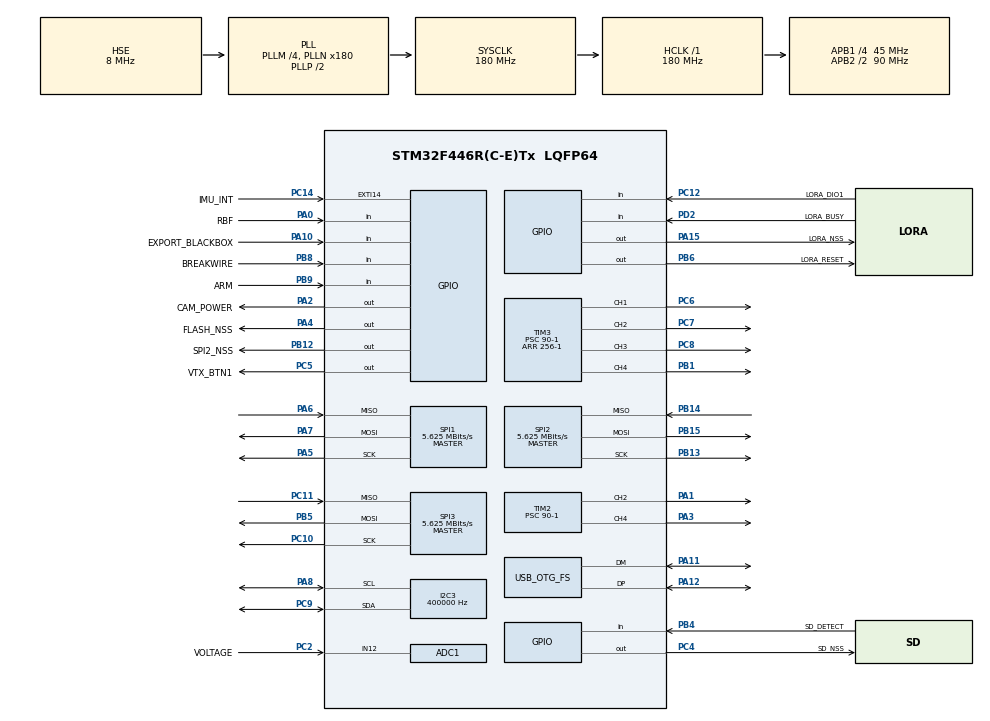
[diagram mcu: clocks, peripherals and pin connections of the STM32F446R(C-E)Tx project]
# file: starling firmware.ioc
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ADC1.Channel-3\#ChannelRegularConversion=ADC_CHANNEL_12
ADC1.NbrOfConversionFlag=1
ADC1.Rank-3\#ChannelRegularConversion=1
ADC1.SamplingTime-3\#ChannelRegularConversion=ADC_SAMPLETIME_3CYCLES
ADC1.master=1
Dma.Request0=SPI2_RX
Dma.Request1=SPI2_TX
Dma.Request2=SPI1_TX
Dma.SPI1_TX.2.Direction=DMA_MEMORY_TO_PERIPH
Dma.SPI1_TX.2.FIFOMode=DMA_FIFOMODE_DISABLE
Dma.SPI1_TX.2.Instance=DMA2_Stream3
Dma.SPI1_TX.2.MemDataAlignment=DMA_MDATAALIGN_BYTE
Dma.SPI1_TX.2.MemInc=DMA_MINC_ENABLE
Dma.SPI1_TX.2.Mode=DMA_NORMAL
Dma.SPI1_TX.2.PeriphDataAlignment=DMA_PDATAALIGN_BYTE
Dma.SPI1_TX.2.PeriphInc=DMA_PINC_DISABLE
Dma.SPI1_TX.2.Priority=DMA_PRIORITY_MEDIUM
Dma.SPI2_RX.0.Direction=DMA_PERIPH_TO_MEMORY
Dma.SPI2_RX.0.FIFOMode=DMA_FIFOMODE_DISABLE
Dma.SPI2_RX.0.Instance=DMA1_Stream3
Dma.SPI2_RX.0.MemDataAlignment=DMA_MDATAALIGN_BYTE
Dma.SPI2_RX.0.MemInc=DMA_MINC_ENABLE
Dma.SPI2_RX.0.Mode=DMA_NORMAL
Dma.SPI2_RX.0.PeriphDataAlignment=DMA_PDATAALIGN_BYTE
Dma.SPI2_RX.0.PeriphInc=DMA_PINC_DISABLE
Dma.SPI2_RX.0.Priority=DMA_PRIORITY_MEDIUM
Dma.SPI2_TX.1.Direction=DMA_MEMORY_TO_PERIPH
Dma.SPI2_TX.1.FIFOMode=DMA_FIFOMODE_DISABLE
Dma.SPI2_TX.1.Instance=DMA1_Stream4
Dma.SPI2_TX.1.MemDataAlignment=DMA_MDATAALIGN_BYTE
Dma.SPI2_TX.1.MemInc=DMA_MINC_ENABLE
Dma.SPI2_TX.1.Mode=DMA_NORMAL
Dma.SPI2_TX.1.PeriphDataAlignment=DMA_PDATAALIGN_BYTE
Dma.SPI2_TX.1.PeriphInc=DMA_PINC_DISABLE
Dma.SPI2_TX.1.Priority=DMA_PRIORITY_MEDIUM
FREERTOS.Queues01=BuzzerQueue,6,uint16_t,0,Dynamic,NULL,NULL
FREERTOS.Tasks01=ledTask,-1,128,StartLedTask,Default,NULL,Dynamic,NULL,NULL;musicTask,-3,128,StartMusicTask,Default,NULL,Dynamic,NULL,NULL;stateMachineTas,2,256,startStateMachine,Default,NULL,Dynamic,NULL,NULL;telemTask,0,256,StartTelemTask,Default,NULL,Dynamic,NULL,NULL;baroTask,0,128,StartBaroTask,Default,NULL,Dynamic,NULL,NULL;blackboxTask,-1,256,StartBlackboxTask,Default,NULL,Dynamic,NULL,NULL
FREERTOS.configENABLE_FPU=1
I2C3.ClockSpeed=400000
I2C3.I2C_Mode=I2C_Fast
Mcu.Family=STM32F4
Mcu.Name=STM32F446R(C-E)Tx
Mcu.Package=LQFP64
NVIC.DMA1_Stream3_IRQn=true\:5\:0\:false\:false\:true\:true\:false\:true
NVIC.DMA1_Stream4_IRQn=true\:5\:0\:false\:false\:true\:true\:false\:true
NVIC.DMA2_Stream3_IRQn=true\:5\:0\:false\:false\:true\:true\:false\:true
NVIC.EXTI15_10_IRQn=true\:5\:0\:false\:false\:true\:true\:true\:true
NVIC.OTG_FS_IRQn=true\:5\:0\:false\:false\:true\:true\:false\:true
NVIC.PriorityGroup=NVIC_PRIORITYGROUP_4
NVIC.TIM1_UP_TIM10_IRQn=true\:0\:0\:false\:false\:true\:false\:false\:true
NVIC.TimeBase=TIM1_UP_TIM10_IRQn
NVIC.TimeBaseIP=TIM1
PA0-WKUP.GPIO_Label=RBF
PA0-WKUP.GPIO_PuPd=GPIO_PULLUP
PA0-WKUP.Signal=GPIO_Input
PA1.Signal=S_TIM2_CH2
PA10.GPIO_Label=EXPORT_BLACKBOX
PA10.GPIO_PuPd=GPIO_PULLUP
PA10.Signal=GPIO_Input
PA11.Mode=Device_Only
PA11.Signal=USB_OTG_FS_DM
PA12.Mode=Device_Only
PA12.Signal=USB_OTG_FS_DP
PA13.Mode=Trace_Asynchronous_SW
PA13.Signal=SYS_JTMS-SWDIO
PA14.Mode=Trace_Asynchronous_SW
PA14.Signal=SYS_JTCK-SWCLK
PA15.GPIO_Label=LORA_NSS
PA15.Signal=GPIO_Output
PA2.GPIO_Label=CAM_POWER
PA2.Signal=GPIO_Output
PA3.Signal=S_TIM2_CH4
PA4.GPIO_Label=FLASH_NSS
PA4.Signal=GPIO_Output
PA5.Mode=Full_Duplex_Master
PA5.Signal=SPI1_SCK
PA6.Mode=Full_Duplex_Master
PA6.Signal=SPI1_MISO
PA7.Mode=Full_Duplex_Master
PA7.Signal=SPI1_MOSI
PA8.Mode=I2C
PA8.Signal=I2C3_SCL
PB1.Signal=S_TIM3_CH4
PB12.GPIO_Label=SPI2_NSS
PB12.Signal=GPIO_Output
PB13.Mode=Full_Duplex_Master
PB13.Signal=SPI2_SCK
PB14.Mode=Full_Duplex_Master
PB14.Signal=SPI2_MISO
PB15.Mode=Full_Duplex_Master
PB15.Signal=SPI2_MOSI
PB3.Mode=Trace_Asynchronous_SW
PB3.Signal=SYS_JTDO-SWO
PB4.GPIO_Label=SD_DETECT
PB4.Signal=GPIO_Input
PB5.Mode=Full_Duplex_Master
PB5.Signal=SPI3_MOSI
PB6.GPIO_Label=LORA_RESET
PB6.PinState=GPIO_PIN_SET
PB6.Signal=GPIO_Output
PB8.GPIO_Label=BREAKWIRE
PB8.GPIO_PuPd=GPIO_PULLUP
PB8.Signal=GPIO_Input
PB9.GPIO_Label=ARM
PB9.GPIO_PuPd=GPIO_PULLUP
PB9.Signal=GPIO_Input
PC10.Mode=Full_Duplex_Master
PC10.Signal=SPI3_SCK
PC11.Mode=Full_Duplex_Master
PC11.Signal=SPI3_MISO
PC12.GPIO_Label=LORA_DIO1
PC12.Signal=GPIO_Input
PC14-OSC32_IN.GPIO_Label=IMU_INT
PC14-OSC32_IN.Signal=GPXTI14
PC2.GPIO_Label=VOLTAGE
PC2.Signal=ADCx_IN12
PC4.GPIO_Label=SD_NSS
PC4.Signal=GPIO_Output
PC5.GPIO_Label=VTX_BTN1
PC5.GPIO_PuPd=GPIO_PULLDOWN
PC5.Signal=GPIO_Output
PC6.Signal=S_TIM3_CH1
PC7.Signal=S_TIM3_CH2
PC8.Signal=S_TIM3_CH3
PC9.Mode=I2C
PC9.Signal=I2C3_SDA
PD2.GPIO_Label=LORA_BUSY
PD2.Signal=GPIO_Input
PH0-OSC_IN.Mode=HSE-External-Oscillator
PH0-OSC_IN.Signal=RCC_OSC_IN
PH1-OSC_OUT.Mode=HSE-External-Oscillator
PH1-OSC_OUT.Signal=RCC_OSC_OUT
ProjectManager.HeapSize=0x200
ProjectManager.StackSize=0x400
ProjectManager.TargetToolchain=STM32CubeIDE
RCC.AHBFreq_Value=180000000
RCC.APB1CLKDivider=RCC_HCLK_DIV4
RCC.APB1Freq_Value=45000000
RCC.APB1TimFreq_Value=90000000
RCC.APB2CLKDivider=RCC_HCLK_DIV2
RCC.APB2Freq_Value=90000000
RCC.APB2TimFreq_Value=180000000
RCC.CortexFreq_Value=180000000
RCC.HCLKFreq_Value=180000000
RCC.HSE_VALUE=8000000
RCC.PLLM=4
RCC.PLLN=180
RCC.PLLQ=8
RCC.PLLSAIM=4
RCC.PLLSAIN=96
RCC.PLLSAIP=RCC_PLLSAIP_DIV4
RCC.PLLSourceVirtual=RCC_PLLSOURCE_HSE
RCC.SYSCLKFreq_VALUE=180000000
RCC.SYSCLKSource=RCC_SYSCLKSOURCE_PLLCLK
RCC.USBCLockSelection=RCC_CLK48CLKSOURCE_PLLSAIP
RCC.USBFreq_Value=48000000
RCC.VCOOutputFreq_Value=360000000
SH.ADCx_IN12.0=ADC1_IN12,IN12
SH.S_TIM2_CH2.0=TIM2_CH2,PWM Generation2 CH2
SH.S_TIM2_CH4.0=TIM2_CH4,PWM Generation4 CH4
SH.S_TIM3_CH1.0=TIM3_CH1,PWM Generation1 CH1
SH.S_TIM3_CH2.0=TIM3_CH2,PWM Generation2 CH2
SH.S_TIM3_CH3.0=TIM3_CH3,PWM Generation3 CH3
SH.S_TIM3_CH4.0=TIM3_CH4,PWM Generation4 CH4
SPI1.BaudRatePrescaler=SPI_BAUDRATEPRESCALER_16
SPI1.CalculateBaudRate=5.625 MBits/s
SPI1.Direction=SPI_DIRECTION_2LINES
SPI1.Mode=SPI_MODE_MASTER
SPI1.VirtualType=VM_MASTER
SPI2.BaudRatePrescaler=SPI_BAUDRATEPRESCALER_8
SPI2.CalculateBaudRate=5.625 MBits/s
SPI2.Direction=SPI_DIRECTION_2LINES
SPI2.Mode=SPI_MODE_MASTER
SPI2.VirtualType=VM_MASTER
SPI3.BaudRatePrescaler=SPI_BAUDRATEPRESCALER_8
SPI3.CalculateBaudRate=5.625 MBits/s
SPI3.Direction=SPI_DIRECTION_2LINES
SPI3.Mode=SPI_MODE_MASTER
SPI3.VirtualType=VM_MASTER
TIM2.Channel-PWM\ Generation2\ CH2=TIM_CHANNEL_2
TIM2.Channel-PWM\ Generation4\ CH4=TIM_CHANNEL_4
TIM2.Period=20000-1
TIM2.Prescaler=90-1
TIM2.Pulse-PWM\ Generation4\ CH4=0
TIM3.Channel-PWM\ Generation1\ CH1=TIM_CHANNEL_1
TIM3.Channel-PWM\ Generation2\ CH2=TIM_CHANNEL_2
TIM3.Channel-PWM\ Generation3\ CH3=TIM_CHANNEL_3
TIM3.Channel-PWM\ Generation4\ CH4=TIM_CHANNEL_4
TIM3.OCPolarity_1=TIM_OCPOLARITY_LOW
TIM3.OCPolarity_3=TIM_OCPOLARITY_LOW
TIM3.OCPolarity_4=TIM_OCPOLARITY_LOW
TIM3.Period=256-1
TIM3.Prescaler=90-1
TIM3.Pulse-PWM\ Generation4\ CH4=0
TIM6.Prescaler=90-1
USB_DEVICE.CLASS_NAME_FS=CDC
USB_DEVICE.VirtualMode-CDC_FS=Cdc
USB_DEVICE.VirtualModeFS=Cdc_FS
USB_OTG_FS.VirtualMode=Device_Only
USB_OTG_FS.low_power_enable=DISABLE
VP_FATFS_VS_Generic.Mode=User_defined
VP_FREERTOS_VS_CMSIS_V1.Mode=CMSIS_V1
VP_SYS_VS_tim1.Mode=TIM1
VP_TIM3_VS_ClockSourceINT.Mode=Internal
VP_TIM6_VS_ClockSourceINT.Mode=Enable_Timer
VP_USB_DEVICE_VS_USB_DEVICE_CDC_FS.Mode=CDC_FS
board=custom

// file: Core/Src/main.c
/* USER CODE BEGIN Header */
/**
 ******************************************************************************
 * @file           : main.c
 * @brief          : Main program body
 ******************************************************************************
 * @attention
 *
 * <h2><center>&copy; Copyright (c) 2021 STMicroelectronics.
 * All rights reserved.</center></h2>
 *
 * This software component is licensed by ST under BSD 3-Clause license,
 * the "License"; You may not use this file except in compliance with the
 * License. You may obtain a copy of the License at:
 *                        opensource.org/licenses/BSD-3-Clause
 *
 ******************************************************************************
 */
/* USER CODE END Header */
#include "main.h"
#include "cmsis_os.h"
#include "fatfs.h"
#include "usb_device.h"

/* USER CODE BEGIN Includes */

#include "usbd_cdc_if.h"
//#include "radio.h"
//#include "sx1280.h"
#include "sx1280_custom.h"
#include "SPL06.h"
#include "LSM6DSO32.h"
#include "servo.h"
#include "Quaternion.h"
#include "orientation.h"
#include "telemetry.h"
#include "w25qxx.h"

/* USER CODE END Includes */

/* USER CODE BEGIN PTD */
typedef enum {
    FLIGHT_ERROR = 0,
    SYSTEMS_CHECK = 1,
    IDLE = 2,
    PREPARATION = 3,
    ARMED = 4,
    LAUNCHED = 5,
    DEPLOYED = 6,
    LANDED = 7,
} state_type;

static state_type flight_state = SYSTEMS_CHECK;

static uint8_t servo_setting = 0;

typedef enum {
    REPEAT_BEEP = 0, KSP_MAIN = 1, RICK = 2, JINGLEBELL = 3,
} buzzer_sound;

static buzzer_sound buzzer_setting = KSP_MAIN;
static uint16_t buzzer_delay = 1000;

// extra (TODO):
uint32_t last_logged_deploy_time = 0;

uint8_t is_camera_recording = 0;
uint8_t is_camera_on = 0;

uint8_t is_data_logging = 0;

uint8_t ranging_enabled = 0;
uint8_t is_ranging_transponder = 0;

char blackbox_printBuffer[256];

flashblock chunk_of_flash;

uint8_t is_tx = 0;

// Music (Rick Astley)

#define  a3f    208     // 208 Hz
#define  b3f    233     // 233 Hz
#define  b3     247     // 247 Hz
#define  c4     261     // 261 Hz MIDDLE C
#define  c4s    277     // 277 Hz
#define  e4f    311     // 311 Hz
#define  f4     349     // 349 Hz
#define  a4f    415     // 415 Hz
#define  b4f    466     // 466 Hz
#define  b4     493     // 493 Hz
#define  c5     523     // 523 Hz
#define  c5s    554     // 554 Hz
#define  e5f    622     // 622 Hz
#define  f5     698     // 698 Hz
#define  f5s    740     // 740 Hz
#define  a5f    831     // 831 Hz

#define rest    -1
static uint16_t song1_intro_melody[] = { c5s, e5f, e5f, f5, a5f, f5s, f5, e5f,
        c5s, e5f, rest, a4f, a4f };

static uint16_t song1_intro_rhythmn[] = { 6, 10, 6, 6, 1, 1, 1, 1, 6, 10, 4, 2,
        10 };

static uint16_t song1_verse1_melody[] = { rest, c4s, c4s, c4s, c4s, e4f, rest,
        c4, b3f, a3f, rest, b3f, b3f, c4, c4s, a3f, a4f, a4f, e4f, rest, b3f,
        b3f, c4, c4s, b3f, c4s, e4f, rest, c4, b3f, b3f, a3f, rest, b3f, b3f,
        c4, c4s, a3f, a3f, e4f, e4f, e4f, f4, e4f, c4s, e4f, f4, c4s, e4f, e4f,
        e4f, f4, e4f, a3f, rest, b3f, c4, c4s, a3f, rest, e4f, f4, e4f };

static uint16_t song1_verse1_rhythmn[] = { 2, 1, 1, 1, 1, 2, 1, 1, 1, 5, 1, 1,
        1, 1, 3, 1, 2, 1, 5, 1, 1, 1, 1, 1, 1, 1, 2, 1, 1, 1, 1, 3, 1, 1, 1, 1,
        2, 1, 1, 1, 1, 1, 1, 4, 5, 1, 1, 1, 1, 1, 1, 1, 2, 2, 2, 1, 1, 1, 3, 1,
        1, 1, 3 };

static uint16_t song1_chorus_melody[] = { b4f, b4f, a4f, a4f, f5, f5, e5f, b4f,
        b4f, a4f, a4f, e5f, e5f, c5s, c5, b4f, c5s, c5s, c5s, c5s, c5s, e5f, c5,
        b4f, a4f, a4f, a4f, e5f, c5s, b4f, b4f, a4f, a4f, f5, f5, e5f, b4f, b4f,
        a4f, a4f, a5f, c5, c5s, c5, b4f, c5s, c5s, c5s, c5s, c5s, e5f, c5, b4f,
        a4f, rest, a4f, e5f, c5s, rest };

static uint16_t song1_chorus_rhythmn[] = { 1, 1, 1, 1, 3, 3, 6, 1, 1, 1, 1, 3,
        3, 3, 1, 2, 1, 1, 1, 1, 3, 3, 3, 1, 2, 2, 2, 4, 8, 1, 1, 1, 1, 3, 3, 6,
        1, 1, 1, 1, 3, 3, 3, 1, 2, 1, 1, 1, 1, 3, 3, 3, 1, 2, 2, 2, 4, 8, 4 };

// Music (KSP main theme)

static uint16_t ksp_tunes[] = {659, 523, 783, 523, 659, 784, 932, 880, 784, 523, 659, 784, 932, 880, 784, 523, 587, 698, 587, 523};
static uint16_t ksp_delays[] = {1000, 1000, 1000, 333, 333, 333, 1000, 1000, 1000, 333, 333, 333, 1000, 1000, 1000, 1000, 1000, 2000, 500, 500};

/* USER CODE END PTD */

/* USER CODE BEGIN PD */

// * 20 ms
#define BEEP_SHORT 12
#define BEEP_NORMAL 25
#define BEEP_LONG 50
#define BEEP_FOREVER 0xFF

#define VBAT_CALIBRATION 0.00456783157 // Based on schematic: 0.004592

// Flight settings:
#define MIN_DEPLOY_TIME 10000 // 10 seconds
#define MAX_DEPLOY_TIME 15000 // 15 seconds

#define BATTERY_EMPTY_LIMIT 7.2 //7.2 // volts
#define SERVO_CLOSED_POSITION 0 // degrees
#define SERVO_DEPLOY_POSITION 180 // degrees

#define OPTIMAL_BUZZER_FREQ 3000
#define OPTIMAL_BUZZER_DUTY 70

/* USER CODE END PD */

ADC_HandleTypeDef hadc1;

I2C_HandleTypeDef hi2c3;

SPI_HandleTypeDef hspi1;
SPI_HandleTypeDef hspi2;
SPI_HandleTypeDef hspi3;
DMA_HandleTypeDef hdma_spi1_tx;
DMA_HandleTypeDef hdma_spi2_rx;
DMA_HandleTypeDef hdma_spi2_tx;

TIM_HandleTypeDef htim2;
TIM_HandleTypeDef htim3;
TIM_HandleTypeDef htim6;

osThreadId ledTaskHandle;
osThreadId musicTaskHandle;
osThreadId stateMachineTasHandle;
osThreadId telemTaskHandle;
osThreadId baroTaskHandle;
osThreadId blackboxTaskHandle;
osMessageQId BuzzerQueueHandle;
/* USER CODE BEGIN PV */

lsm6dso imu;
uint8_t imu_ready = 0;

Orientation ori;
uint8_t apply_complementary = 1;

SPL06 baro;

/* USER CODE END PV */

void SystemClock_Config(void);
static void MX_GPIO_Init(void);
static void MX_DMA_Init(void);
static void MX_TIM3_Init(void);
static void MX_SPI2_Init(void);
static void MX_SPI3_Init(void);
static void MX_TIM2_Init(void);
static void MX_SPI1_Init(void);
static void MX_I2C3_Init(void);
static void MX_ADC1_Init(void);
static void MX_TIM6_Init(void);
void StartLedTask(void const * argument);
void StartMusicTask(void const * argument);
void startStateMachine(void const * argument);
void StartTelemTask(void const * argument);
void StartBaroTask(void const * argument);
void StartBlackboxTask(void const * argument);

/* USER CODE BEGIN PFP */

void playtone(uint16_t freq, uint16_t ms, uint8_t vol);
void changeLed(uint8_t ledR, uint8_t ledG, uint8_t ledB);
void jingleBell();
void rick();
void ksp();

float get_battery_voltage() {
    HAL_ADC_Start(&hadc1);
    HAL_ADC_PollForConversion(&hadc1, 100);
    float voltage = ((float) HAL_ADC_GetValue(&hadc1)) * VBAT_CALIBRATION;
    return voltage;
}

uint8_t is_armed() {
    return HAL_GPIO_ReadPin(RBF_GPIO_Port, RBF_Pin);// High corresponds to disconected = armed
}

uint8_t is_armed_debounce() {
    for (int i = 0; i < 20; i++) {
        if (!is_armed()) {
            return 0;
        }
        osDelay(1);
    }
    return 1;
}

uint8_t is_soft_enabled() {
    return HAL_GPIO_ReadPin(ARM_GPIO_Port, ARM_Pin);
}

uint8_t is_breakwire_connected() {
    return !HAL_GPIO_ReadPin(BREAKWIRE_GPIO_Port, BREAKWIRE_Pin);
}

uint8_t is_breakwire_broken_debounce() {
    for (int i = 0; i < 20; i++) {
        if (is_breakwire_connected()) {
            return 0;
        }
        osDelay(1);
    }
    return 1;
}

void buzzer_beep(uint8_t delayval) {
    buzzer_setting = REPEAT_BEEP;
    buzzer_delay = delayval * 20;

    if (osMessageAvailableSpace(BuzzerQueueHandle)) {
        osMessagePut(BuzzerQueueHandle, buzzer_delay, 100);
    }
}

void buzzer_clear_queue() {
    xQueueReset(BuzzerQueueHandle);
}

void pulse_recording_button() {
    HAL_GPIO_WritePin(VTX_BTN1_GPIO_Port, VTX_BTN1_Pin, GPIO_PIN_SET);
    osDelay(300);
    HAL_GPIO_WritePin(VTX_BTN1_GPIO_Port, VTX_BTN1_Pin, GPIO_PIN_RESET);
}

void double_pulse_recording() {
    HAL_GPIO_WritePin(VTX_BTN1_GPIO_Port, VTX_BTN1_Pin, GPIO_PIN_SET);
    osDelay(300);
    HAL_GPIO_WritePin(VTX_BTN1_GPIO_Port, VTX_BTN1_Pin, GPIO_PIN_RESET);
    osDelay(1000);
    HAL_GPIO_WritePin(VTX_BTN1_GPIO_Port, VTX_BTN1_Pin, GPIO_PIN_SET);
    osDelay(300);
    HAL_GPIO_WritePin(VTX_BTN1_GPIO_Port, VTX_BTN1_Pin, GPIO_PIN_RESET);

}

void enable_recording() {
    if (!is_camera_recording) {
        pulse_recording_button();
        is_camera_recording = 1;
    }
}

void disable_recording() {
    if (is_camera_recording) {
        pulse_recording_button();
        is_camera_recording = 0;
    }
}

void enable_camera() {
    HAL_GPIO_WritePin(CAM_POWER_GPIO_Port, CAM_POWER_Pin, GPIO_PIN_SET);
    is_camera_recording = 0;
    is_camera_on = 1;
}

void disable_camera() {
    if (is_camera_recording) {
        pulse_recording_button();
        osDelay(1000);
        is_camera_recording = 0;
    }
    is_camera_on = 0;
    HAL_GPIO_WritePin(CAM_POWER_GPIO_Port, CAM_POWER_Pin, GPIO_PIN_RESET);
}

void restart_camera_with_recording() {
    disable_camera();
    osDelay(300);
    enable_camera();
    osDelay(10000);
    enable_recording();
}

void set_status_led(uint8_t status_state) {
    // TODO
}

uint8_t is_vote_asserted() {
    // Todo
    return 0;
}

void rangingTransponder() {
    sx1280_custom radio;

        sxInit(&radio, &hspi3, LORA_NSS_GPIO_Port, LORA_NSS_Pin);
        sxSetDio1Pin(&radio, LORA_DIO1_GPIO_Port, LORA_DIO1_Pin);
        HAL_Delay(1);
        SetStandbyRC(&radio);
        HAL_Delay(1);
        setPacketRanging(&radio);
        HAL_Delay(1);
        SetModulationParams(&radio, 0x80, 0x18, 0x01);
        HAL_Delay(1);
        SetPacketParamsLora(&radio, 12, 0x80, 0, 0x20, 0x40);
        HAL_Delay(1);
        SetRfFrequency(&radio);
        HAL_Delay(1);
        SetTxParams(&radio, 0x1F, 0xE0); // Power = 13 dBm (0x1F), Pout = -18 + power (dBm) ramptime = 20 us.
        HAL_Delay(5);
        sxStandardRangingSlave(&radio);
        HAL_Delay(3);
        uint16_t mask = 1 << 7 | 1<<11 | 1<<14 | 1<<8;
        SetDioIrqParams(&radio,mask ,mask, 0, 0);
        HAL_Delay(1);

        changeLed(0, 0, 50);

        char printBuffer[128];

        HAL_Delay(1);
        for (;;) {
            ClrIrqStatus(&radio, mask);
            HAL_Delay(1);

            SetRx(&radio, 0x02, 1000);
            HAL_Delay(1);
            for (int i = 0; i < 1000; i++) {
                if (HAL_GPIO_ReadPin(LORA_DIO1_GPIO_Port, LORA_DIO1_Pin)) {
                    break;
                }
                HAL_Delay(1);
            }
            GetIrqStatus(&radio);
            sprintf(printBuffer, "%d\r\n",radio.IrqStatus);

            CDC_Transmit_FS((uint8_t*) printBuffer,
                    MIN(strlen(printBuffer), 128));

            changeLed(200, 200, 200);
            HAL_Delay(10);
            changeLed(0, 0, 50);

            HAL_Delay(1);
        }
}

void loraTesting(uint8_t isTx) {

    sx1280_custom radio;
    sxInit(&radio, &hspi3, LORA_NSS_GPIO_Port, LORA_NSS_Pin);

    if (isTx) {
        //SetTxParams(0x06, 0xE0); // Power = 13 dBm (0x1F), Pout = -18 + power (dBm) ramptime = 20 us.
        //SetTxParams(0x00, 0xE0); // lowest power -18dBm
        SetTxParams(&radio, 31, 0xE0); // Highest power. 12.5 dBm
        HAL_Delay(3);

        uint8_t data[] = { 0, 0, 0, 0 };

        WriteBuffer(&radio, 0, data, sizeof(data));
        HAL_Delay(1);

        SetDioIrqParams(&radio, 1, 1, 0, 0); // txdone on gpio1

        //SetTxContinuousWave();
        HAL_Delay(3);

        uint8_t ledon = 0;

        while (1) {
            ledon = !ledon;
            //data[1] = (rand()%5) * 30;
            //data[2] = (rand()%5) * 30;
            //data[3] = (rand()%5) * 30;
            data[2] = ledon * 100;

            changeLed(data[1], data[2], data[3]);

            WriteBuffer(&radio, 0, data, sizeof(data));
            HAL_Delay(1);
            ClrIrqStatus(&radio, 1); // clear txdone irq
            HAL_Delay(1);
            SetTx(&radio, 0x02, 50); // time-out of 1ms * 50 = 50ms
            //SetRfFrequency2();
            //HAL_Delay(5000);
            //SetRfFrequency();
            //changeLed(0, 100, 0);
            HAL_Delay(500);
        }
    } else {
        // rx mode
        SetDioIrqParams(&radio, 1 << 1, 1 << 1, 0, 0); //rxdone on gpio1
        HAL_Delay(1);

        uint8_t data[32];
        data[0] = 60;
        data[1] = 60;
        data[2] = 60;
        uint8_t rxStartBufferPointer = 1;

        changeLed(0, 100, 0);
        uint8_t counter = 0;

        while (1) {

            //SetRx(0x00, 0xffff); // continous rx
            SetRx(&radio, 0x00, 0); // No timeout
            //SetRx(0x02, 200); // 200 ms timeout
            HAL_Delay(1);
            // wait for reception:
            while (!HAL_GPIO_ReadPin(LORA_DIO1_GPIO_Port, LORA_DIO1_Pin)) {
            }

            //GetPacketStatus(); // TODO
            ClrIrqStatus(&radio, 1 << 1); // clear rxdone Irq
            HAL_Delay(1);
            //GetRxBufferStatus(); // TODO
            ReadBuffer(&radio, rxStartBufferPointer, 32, data);
            changeLed(data[1], data[2], data[3]);
            if (data[2]) {
                htim2.Instance->CCR4 = 1000;
            } else {
                htim2.Instance->CCR4 = 2000;
            }

            HAL_Delay(10);

        }

    }
}

void loraOrientation(uint8_t isTx) {

    sx1280_custom radio;

    sxInit(&radio, &hspi3, LORA_NSS_GPIO_Port, LORA_NSS_Pin);
    sxSetDio1Pin(&radio, LORA_DIO1_GPIO_Port, LORA_DIO1_Pin);

    float data[4];

    char printBuffer[128];

    if (isTx) {
        //SetTxParams(0x06, 0xE0); // Power = 13 dBm (0x1F), Pout = -18 + power (dBm) ramptime = 20 us.
        SetTxParams(&radio, 0, 0xE0); // lowest power -18dBm
        HAL_Delay(3);

        lsm6dso imu;
        uint8_t lsm_init_status = LSM_init(&imu, &hspi2, SPI2_NSS_GPIO_Port,
        SPI2_NSS_Pin);

        Orientation ori;
        orientation_init(&ori);
        uint32_t counter = 0;

        data[0] = ori.orientationQuat.w;
        data[1] = ori.orientationQuat.v[0];
        data[2] = ori.orientationQuat.v[1];
        data[3] = ori.orientationQuat.v[2];

        WriteBuffer(&radio, 0, (uint8_t*) data, sizeof(data));
        HAL_Delay(1);

        SetDioIrqParams(&radio, 1, 1, 0, 0); // txdone on gpio1

        HAL_Delay(3);

        uint32_t lasttime = HAL_GetTick();
        uint32_t nowtime = HAL_GetTick();
        float dt = 0;
        changeLed(100, 100, 100);

        while (1) {

            LSM_pollsensors(&imu);
            changeLed(0, 0, 100);
            nowtime = HAL_GetTick();
            dt = (nowtime - lasttime) / 1000.0;
            lasttime = nowtime;

            orientation_setGyro(&ori, imu.gyroRPS);
            orientation_setAcc(&ori, imu.accMPS);
            orientation_update(&ori, dt, 1);

            counter++;

            if (counter % 20 == 0) {
                data[0] = ori.orientationQuat.w;
                data[1] = ori.orientationQuat.v[0];
                data[2] = ori.orientationQuat.v[1];
                data[3] = ori.orientationQuat.v[2];

                sprintf(printBuffer, "Quaternion: %f, %f, %f, %f\r\n", data[0],
                        data[1], data[2], data[3]);
                //sprintf(printBuffer, "Quaternion: %f, %f, %f, %f\r\n",data[0],ori.orientationQuat.v[0],ori.orientationQuat.v[1],ori.orientationQuat.v[2]);
                CDC_Transmit_FS((uint8_t*) printBuffer,
                        MIN(strlen(printBuffer), 128));

                WriteBuffer(&radio, 0, (uint8_t*) data, sizeof(data));
                HAL_Delay(1);
                ClrIrqStatus(&radio, 1); // clear txdone irq
                HAL_Delay(1);
                SetTx(&radio, 0x02, 50); // time-out of 1ms * 50 = 50ms
            }

            HAL_Delay(1);

        }
    } else {
        // rx mode
        SetDioIrqParams(&radio, 1 << 1, 1 << 1, 0, 0); //rxdone on gpio1
        HAL_Delay(1);

        uint8_t rxStartBufferPointer = 1;

        changeLed(0, 100, 0);
        while (1) {

            //SetRx(0x00, 0xffff); // continous rx
            SetRx(&radio, 0x00, 0); // No timeout
            //SetRx(0x02, 200); // 200 ms timeout
            HAL_Delay(1);
            // wait for reception:
            while (!HAL_GPIO_ReadPin(LORA_DIO1_GPIO_Port, LORA_DIO1_Pin)) {
            }

            GetPacketStatusLora(&radio);
            ClrIrqStatus(&radio, 1 << 1); // clear rxdone Irq
            HAL_Delay(1);
            //GetRxBufferStatus(); // TODO

            ReadBuffer(&radio, rxStartBufferPointer, sizeof(data),
                    (uint8_t*) data);
            snprintf(printBuffer, 128,
                    "Quaternion: %f, %f, %f, %f, RSSI: %f, SNR: %f\r\n",
                    data[0], data[1], data[2], data[3], radio.rssi, radio.snr);
            CDC_Transmit_FS((uint8_t*) printBuffer, strlen(printBuffer));
            HAL_Delay(1);

        }

    }
}

void loraTelemetry() {
    TLM_decoded TLM_dec;
    TLM_encoded TLM_enc;

    sx1280_custom radio;

    sxInit(&radio, &hspi3, LORA_NSS_GPIO_Port, LORA_NSS_Pin);
    sxSetDio1Pin(&radio, LORA_DIO1_GPIO_Port, LORA_DIO1_Pin);

    char printBuffer[256];

    // rx mode
    SetDioIrqParams(&radio, 1 | (1 << 1) | (1 << 6), 1 | 1 << 1, 0, 0); //rxdone/txdone on gpio1, crcerror on as well
    HAL_Delay(1);
    SetTxParams(&radio, 0x1F, 0xE0);
    HAL_Delay(1);

    uint8_t rxStartBufferPointer = 0;
    /*
    TLM_dec.packet_type = 1;
    TLM_dec.flight_state = 23;
    TLM_dec.is_playing_music = 0;
    TLM_dec.is_data_logging = 0;
    TLM_dec.pin_states = 0b00011011;
    TLM_dec.servo_state = 3;
    TLM_dec.vbat = 7.283;
    TLM_dec.systick = 1232432;
    TLM_dec.orientation_quat[0] = 0.143123;
    TLM_dec.acc[2] = -12343;
    TLM_dec.gyro[2] = -21;
    TLM_dec.baro = 90001.623;
    TLM_dec.temp = 63.4;
    TLM_dec.vertical_velocity = 180;
    TLM_dec.altitude = 1321;
    TLM_dec.debug = 1337;
    TLM_dec.ranging = 15212;

     */

    float latitude = 52.394821;
    float longitude = 5.922696;

    float acc_conversion = 0.0095712904;
    float gyro_conversion = 0.00122173047; //0.070;

    uint32_t pkt_count = 0;

    //changeLed(0, 100, 0);
    uint8_t data[4];
    uint32_t lasttime = HAL_GetTick();
    uint32_t nowtime = HAL_GetTick();
    uint32_t delay = 0;

    uint8_t is_soft_enabled;
    uint8_t is_armed ;
    uint8_t is_breakwire_connected;
    uint8_t is_camera_on;

    uint8_t button_pressed = 0;

    uint8_t controlData[4];

    uint8_t last_cam_control_state = 1;
    uint8_t debounce_helper = 0;
    while (1) {

        //SetRx(0x00, 0xffff); // continous rx
        SetRx(&radio, 0x00, 0); // No timeout
        //SetRx(0x02, 200); // 200 ms timeout
        HAL_Delay(1);
        // wait for reception:
        for (int i = 0; i < 70; i++) { // 50 ms timeout
            if (HAL_GPIO_ReadPin(LORA_DIO1_GPIO_Port, LORA_DIO1_Pin)) {
                nowtime = HAL_GetTick();
                delay = nowtime - lasttime  ;
                lasttime = nowtime;
                break;
            }
            HAL_Delay(1);
        }

        if (HAL_GPIO_ReadPin(LORA_DIO1_GPIO_Port, LORA_DIO1_Pin)) {

            pkt_count++;

            GetPacketStatusLora(&radio);
            GetIrqStatus(&radio);

            ClrIrqStatus(&radio, 1 | (1 << 1) | (1 << 6)); // clear rxdone/txdone Irq and crcerror
            HAL_Delay(1);
            //GetRxBufferStatus(); // TODO

            ReadBuffer(&radio, rxStartBufferPointer, sizeof(TLM_enc),
                    (uint8_t*) &TLM_enc);
            //ReadBuffer(&radio, rxStartBufferPointer, sizeof(data), (uint8_t*) data);
            decode_TLM(&TLM_enc, &TLM_dec);
            //snprintf(printBuffer, 128, "%d,%d,%d,%d,%d,%d,%f,%d,%f,%d,%d,%f,%f,%f,%f,%f\r\n", TLM_dec.packet_type,TLM_dec.flight_state,TLM_dec.is_playing_music,TLM_dec.is_data_logging,
            //        TLM_dec.pin_states,TLM_dec.servo_state, TLM_dec.vbat, TLM_dec.systick, TLM_dec.orientation_quat[0], TLM_dec.acc[2],TLM_dec.gyro[2],TLM_dec.baro, TLM_dec.temp, TLM_dec.vertical_velocity,
            //        TLM_dec.altitude, TLM_dec.ranging);

            is_soft_enabled = (TLM_dec.pin_states & 1);
            is_armed = (TLM_dec.pin_states & (1 << 1)) >> 1;
            is_breakwire_connected = (TLM_dec.pin_states & (1 << 2)) >> 2;
            is_camera_on = (TLM_dec.pin_states & (1 << 3)) >> 3;

            snprintf(printBuffer, 256,
                    "/*Project Zeggreus,%ld,%ld,%f,%f,%f,%f,%f,%ld,%ld,%f,%f,%f,%f,%f,%f,%f,%f,%f,%f,%f,%d,%d,%d,%d,%d,%d,%d,%f,%f,%f,%f*/\r\n",
                    TLM_dec.systick, pkt_count, TLM_dec.vbat, TLM_dec.temp,
                    TLM_dec.altitude, TLM_dec.baro / 1000, TLM_dec.temp, delay,
                    TLM_dec.systick, longitude, latitude, TLM_dec.altitude, 0.0,
                    TLM_dec.acc[0] * acc_conversion,
                    TLM_dec.acc[1] * acc_conversion,
                    TLM_dec.acc[2] * acc_conversion,
                    TLM_dec.gyro[0] * gyro_conversion,
                    TLM_dec.gyro[1] * gyro_conversion,
                    TLM_dec.gyro[2] * gyro_conversion, radio.rssi,
                    radio.crcError, 1, is_soft_enabled, is_armed,
                    is_breakwire_connected, is_camera_on,TLM_dec.flight_state), TLM_dec.orientation_quat[0],TLM_dec.orientation_quat[1],TLM_dec.orientation_quat[2],TLM_dec.orientation_quat[3];

            //snprintf(printBuffer, 128, "Quaternion:%f, %f, %f, %f\r\n", TLM_dec.orientation_quat[0], TLM_dec.orientation_quat[1], TLM_dec.orientation_quat[2], TLM_dec.orientation_quat[3]);
            //snprintf(printBuffer, 128,
            //       "Quaternion: %d, %d, %d, %d, RSSI: %f, SNR: %f\r\n",
            //       data[0], data[1], data[2], data[3], radio.rssi, radio.snr);
            CDC_Transmit_FS((uint8_t*) printBuffer, strlen(printBuffer));

        } else {
        }

        HAL_Delay(1);

    }

}

void servoToggleTest() {
    while (1) {
        htim2.Instance->CCR4 = 1000;
        HAL_Delay(2000);
        htim2.Instance->CCR4 = 2000;
        HAL_Delay(2000);

    };
}

void infiniteKSP() {
    while (1) {
        ksp();
    };
}

void startupMusic() {
    // Startup sound
    changeLed(100, 34, 20);

    changeLed(255, 0, 0);
    playtone(1046, 100, 10);
    HAL_Delay(100);
    changeLed(0, 255, 0);
    playtone(1319, 100, 10);
    return;
    HAL_Delay(100);
    changeLed(0, 0, 255);
    playtone(1175, 100, 20);
    HAL_Delay(100);

    changeLed(255, 0, 255);
    playtone(1568, 200, 30);
    HAL_Delay(300);
    //playtone(988, 200, 30);

    for (int i = 1400; i < 1900; i += 100) {

        uint32_t aar_val = 1e6 / (i);
        htim3.Instance->ARR = aar_val;
        htim3.Instance->CCR2 = aar_val * 10 / (2 * 100);

        changeLed((i - 1400) / 3, (i - 1400) / 3, (i - 1400) / 3);
        HAL_Delay(100);

        // reset to defaults
        //htim3.Instance->CCR2 = 0;
        //htim3.Instance->ARR = 256 - 1;
    }
}

void SDTesting() {
    // LSM6dso setup
    lsm6dso imu;
    uint8_t lsm_init_status = LSM_init(&imu, &hspi2, SPI2_NSS_GPIO_Port,
    SPI2_NSS_Pin);
    uint8_t sd_mounted = !HAL_GPIO_ReadPin(SD_DETECT_GPIO_Port, SD_DETECT_Pin);

    if (!sd_mounted) {
        while (1) {
            changeLed(0, 0, 100);
            HAL_Delay(1000);
        }
    }

    changeLed(0, 0, 0);

    HAL_Delay(5000);

    changeLed(100, 100, 100);
    char printBuffer[128];
    sprintf(printBuffer, "SD CARD TEST!\r\n");

    CDC_Transmit_FS((uint8_t*) printBuffer, strlen(printBuffer));

    FATFS FatFs;  //Fatfs handle
    FIL fil;      //File handle
    FRESULT fres; //Result after operations

    //Open the file system
    fres = f_mount(&FatFs, "", 1); //1=mount now
    if (fres != FR_OK) {
        sprintf(printBuffer, "f_mount error (%i)\r\n", fres);
        CDC_Transmit_FS((uint8_t*) printBuffer, strlen(printBuffer));
        while (1) {
            CDC_Transmit_FS((uint8_t*) printBuffer, strlen(printBuffer));
            HAL_Delay(100);
        }
    }

    //Let's get some statistics from the SD card
    DWORD free_clusters, free_sectors, total_sectors;

    FATFS *getFreeFs;

    fres = f_getfree("", &free_clusters, &getFreeFs);
    if (fres != FR_OK) {
        sprintf(printBuffer, "f_getfree error (%i)\r\n", fres);

        CDC_Transmit_FS((uint8_t*) printBuffer, strlen(printBuffer));
        while (1)
            ;
    }

    //Formula comes from ChaN's documentation
    total_sectors = (getFreeFs->n_fatent - 2) * getFreeFs->csize;
    free_sectors = free_clusters * getFreeFs->csize;

    sprintf(printBuffer,
            "SD card stats:\r\n%10lu KiB total drive space.\r\n%10lu KiB available.\r\n",
            total_sectors / 2, free_sectors / 2);

    CDC_Transmit_FS((uint8_t*) printBuffer, strlen(printBuffer));

    //Now let's try to open file "test.txt"
    fres = f_open(&fil, "hello.txt", FA_READ);
    if (fres != FR_OK) {
        sprintf(printBuffer, "f_open error\r\n");

        CDC_Transmit_FS((uint8_t*) printBuffer, strlen(printBuffer));
        while (1)
            ;
    }

    sprintf(printBuffer, "I was able to open 'hello.txt' for reading!\r\n");
    CDC_Transmit_FS((uint8_t*) printBuffer, strlen(printBuffer));

    //Read 30 bytes from "test.txt" on the SD card
    BYTE readBuf[128];

    //We can either use f_read OR f_gets to get data out of files
    //f_gets is a wrapper on f_read that does some string formatting for us
    TCHAR *rres = f_gets((TCHAR*) readBuf, 30, &fil);
    if (rres != 0) {
        sprintf(printBuffer, "Read string from 'test.txt' contents: %s\r\n",
                readBuf);
        CDC_Transmit_FS((uint8_t*) printBuffer, strlen(printBuffer));
    } else {
        sprintf(printBuffer, "f_gets error (%i)\r\n", fres);
        CDC_Transmit_FS((uint8_t*) printBuffer, strlen(printBuffer));
    }

    //Be a tidy kiwi - don't forget to close your file!
    f_close(&fil);

    //Now let's try and write a file "write.txt"
    fres = f_open(&fil, "write.txt",
    FA_WRITE | FA_OPEN_ALWAYS | FA_CREATE_ALWAYS);
    if (fres == FR_OK) {
        sprintf(printBuffer, "I was able to open 'write.txt' for writing\r\n");
        CDC_Transmit_FS((uint8_t*) printBuffer, strlen(printBuffer));
    } else {
        sprintf(printBuffer, "f_open error (%i)\r\n", fres);
        CDC_Transmit_FS((uint8_t*) printBuffer, strlen(printBuffer));
    }

    //Copy in a string
    strncpy((char*) readBuf, "a new file is made!", 19);
    UINT bytesWrote;
    fres = f_write(&fil, readBuf, 19, &bytesWrote);
    if (fres == FR_OK) {
        sprintf(printBuffer, "Wrote %i bytes to 'write.txt'!\r\n", bytesWrote);
        CDC_Transmit_FS((uint8_t*) printBuffer, strlen(printBuffer));
    } else {
        sprintf(printBuffer, "f_write error (%i)\r\n");
        CDC_Transmit_FS((uint8_t*) printBuffer, strlen(printBuffer));
    }

    //Be a tidy kiwi - don't forget to close your file!
    f_close(&fil);

    changeLed(0, 200, 200);

    f_open(&fil, "gyro.csv", FA_WRITE | FA_OPEN_ALWAYS | FA_CREATE_ALWAYS);

    sprintf(printBuffer, "t,gx,gy,gz\r\n");
    strncpy((char*) readBuf, printBuffer, strlen(printBuffer));
    fres = f_write(&fil, readBuf, strlen(printBuffer), &bytesWrote);

    for (uint16_t i = 0; i < 15 * 1000; i++) { // 15 second test
        HAL_Delay(1);
        LSM_pollsensors(&imu);

        sprintf(printBuffer, "%d,%d,%d,%d\r\n", HAL_GetTick(), imu.rawGyro[1],
                (-1) * imu.rawGyro[0], imu.rawGyro[2]);
        strncpy((char*) readBuf, printBuffer, strlen(printBuffer));
        fres = f_write(&fil, readBuf, strlen(printBuffer), &bytesWrote);
    }
    f_close(&fil);

    //We're done, so de-mount the drive
    f_mount(NULL, "", 0);

    while (1) {
        changeLed(0, 200, 0);
        HAL_Delay(40);

    }

}

/* USER CODE END PFP */

/* USER CODE BEGIN 0 */

void HAL_GPIO_EXTI_Callback(uint16_t GPIO_Pin) {
    if (GPIO_Pin == IMU_INT_Pin && imu_ready) {
        LSM_ReadDMA(&imu);
    }
}

void HAL_SPI_TxRxCpltCallback(SPI_HandleTypeDef *hspi) {
    if (hspi->Instance == SPI2) {
        LSM_ReadDMA_Complete(&imu);
    }
}

/* USER CODE END 0 */

int main(void)
{

  /* MCU Configuration--------------------------------------------------------*/

  /* Reset of all peripherals, Initializes the Flash interface and the Systick. */
  HAL_Init();

  /* Configure the system clock */
  SystemClock_Config();

  /* Initialize all configured peripherals */
  MX_GPIO_Init();
  MX_DMA_Init();
  MX_TIM3_Init();
  MX_SPI2_Init();
  MX_SPI3_Init();
  MX_TIM2_Init();
  MX_SPI1_Init();
  MX_FATFS_Init();
  MX_I2C3_Init();
  MX_ADC1_Init();
  MX_TIM6_Init();
  /* USER CODE BEGIN 2 */
    HAL_TIM_PWM_Start(&htim3, TIM_CHANNEL_4);
    HAL_TIM_PWM_Start(&htim3, TIM_CHANNEL_2);
    HAL_TIM_PWM_Start(&htim3, TIM_CHANNEL_3);
    HAL_TIM_PWM_Start(&htim3, TIM_CHANNEL_1);

    HAL_TIM_PWM_Start(&htim2, TIM_CHANNEL_4);

    HAL_TIM_Base_Start(&htim6);

    /* init code for USB_DEVICE */
    MX_USB_DEVICE_Init();

    startupMusic();
    //while (1) {rick();}

    changeLed(90, 0, 0);

    htim3.Instance->CCR2 = 0;
    htim3.Instance->ARR = 256 - 1;

    char printBuffer[128];
    HAL_Delay(500);

    //BWtest();

    //loraTesting(is_tx);
    // setting to go into ground station mode
    if (!is_tx) {
        loraTelemetry();
    }
    if (is_ranging_transponder) {
        rangingTransponder();
    }
    //servoToggleTest();
    if (!HAL_GPIO_ReadPin(EXPORT_BLACKBOX_GPIO_Port, EXPORT_BLACKBOX_Pin)) {

        W25qxx_Initnon();
        changeLed(200, 200, 200);
        playtone(1000, 1000, 50);
        HAL_Delay(10000);

        TLM_decoded flash_dec;
        uint32_t counter = 0;

        uint8_t testblock[100];
        testblock[0] = 110;
        testblock[1] = 123;

        // wait 10 sec.
        while (counter < 65536) {
            //W25qxx_WritePage(testblock, counter, 0, 100);
            W25qxx_ReadPageNon((uint8_t*) &chunk_of_flash, counter, 0, 256);
            playtone(1000, 8, 50);
            //uint32_t uid = W25qxx_ReadID();
            HAL_Delay(1);

            for (int j = 0; j < 7; j++) {
                decode_Blackbox(&chunk_of_flash.packets[j], &flash_dec);
                sprintf(blackbox_printBuffer,
                        "%d,%d,%d,%d,%ld,%f,%f,%f,%f,%f,%ld,%ld,%ld,%ld,%ld,%ld,%f,%f,%f,%f\r\n",
                        chunk_of_flash.blockinfo[0], flash_dec.packet_type, flash_dec.flight_state,
                        flash_dec.pin_states, flash_dec.systick,
                        flash_dec.vbat, flash_dec.orientation_quat[0],
                        flash_dec.orientation_quat[1],
                        flash_dec.orientation_quat[2],
                        flash_dec.orientation_quat[3], flash_dec.acc[0],
                        flash_dec.acc[1], flash_dec.acc[2],
                        flash_dec.gyro[0], flash_dec.gyro[1],
                        flash_dec.gyro[2], flash_dec.baro, flash_dec.temp,
                        flash_dec.altitude, flash_dec.vertical_velocity);
                //sprintf(blackbox_printBuffer,"%ld\r\n",uid);

                CDC_Transmit_FS((uint8_t*) blackbox_printBuffer,
                        MIN(strlen(blackbox_printBuffer), 256));
                HAL_Delay(15);
            }

            counter++;
            HAL_Delay(10);

       }

       changeLed(0, 0, 200);

    }

    // LSM6dso setup
    orientation_init(&ori);
    uint8_t lsm_init_status = LSM_init(&imu, &hspi2, SPI2_NSS_GPIO_Port, SPI2_NSS_Pin);
    __HAL_TIM_SET_COUNTER(&htim6,0);
    imu_ready = 1;

    uint8_t barostatus = SPL06_Init(&baro, &hi2c3, 0x77);

    if (barostatus != 5) {

            HAL_Delay(100);
            changeLed(100, 0, 0);
            HAL_Delay(100);
            changeLed(0, 0, 0);

    }

    //SDTesting();

    float yrot = 0;
    uint32_t lasttime = HAL_GetTick();
    uint32_t nowtime = HAL_GetTick();
    float dt = 0;

    uint16_t rawadc;

    uint32_t counter = 0;

  /* USER CODE END 2 */

  /* Create the queue(s) */
  /* definition and creation of BuzzerQueue */
  osMessageQDef(BuzzerQueue, 6, uint16_t);
  BuzzerQueueHandle = osMessageCreate(osMessageQ(BuzzerQueue), NULL);

  /* Create the thread(s) */
  /* definition and creation of ledTask */
  osThreadDef(ledTask, StartLedTask, osPriorityBelowNormal, 0, 128);
  ledTaskHandle = osThreadCreate(osThread(ledTask), NULL);

  /* definition and creation of musicTask */
  osThreadDef(musicTask, StartMusicTask, osPriorityIdle, 0, 128);
  musicTaskHandle = osThreadCreate(osThread(musicTask), NULL);

  /* definition and creation of stateMachineTas */
  osThreadDef(stateMachineTas, startStateMachine, osPriorityHigh, 0, 256);
  stateMachineTasHandle = osThreadCreate(osThread(stateMachineTas), NULL);

  /* definition and creation of telemTask */
  osThreadDef(telemTask, StartTelemTask, osPriorityNormal, 0, 256);
  telemTaskHandle = osThreadCreate(osThread(telemTask), NULL);

  /* definition and creation of baroTask */
  osThreadDef(baroTask, StartBaroTask, osPriorityNormal, 0, 128);
  baroTaskHandle = osThreadCreate(osThread(baroTask), NULL);

  /* definition and creation of blackboxTask */
  osThreadDef(blackboxTask, StartBlackboxTask, osPriorityBelowNormal, 0, 256);
  blackboxTaskHandle = osThreadCreate(osThread(blackboxTask), NULL);

  /* Start scheduler */
  osKernelStart();

  /* We should never get here as control is now taken by the scheduler */
  /* Infinite loop */
    while (1) {

    /* USER CODE BEGIN 3 */

        HAL_Delay(1);

    }
  /* USER CODE END 3 */
}

void SystemClock_Config(void)
{
  RCC_OscInitTypeDef RCC_OscInitStruct = {0};
  RCC_ClkInitTypeDef RCC_ClkInitStruct = {0};
  RCC_PeriphCLKInitTypeDef PeriphClkInitStruct = {0};

  /** Configure the main internal regulator output voltage
  */
  __HAL_RCC_PWR_CLK_ENABLE();
  __HAL_PWR_VOLTAGESCALING_CONFIG(PWR_REGULATOR_VOLTAGE_SCALE1);
  /** Initializes the RCC Oscillators according to the specified parameters
  * in the RCC_OscInitTypeDef structure.
  */
  RCC_OscInitStruct.OscillatorType = RCC_OSCILLATORTYPE_HSE;
  RCC_OscInitStruct.HSEState = RCC_HSE_ON;
  RCC_OscInitStruct.PLL.PLLState = RCC_PLL_ON;
  RCC_OscInitStruct.PLL.PLLSource = RCC_PLLSOURCE_HSE;
  RCC_OscInitStruct.PLL.PLLM = 4;
  RCC_OscInitStruct.PLL.PLLN = 180;
  RCC_OscInitStruct.PLL.PLLP = RCC_PLLP_DIV2;
  RCC_OscInitStruct.PLL.PLLQ = 8;
  RCC_OscInitStruct.PLL.PLLR = 2;
  if (HAL_RCC_OscConfig(&RCC_OscInitStruct) != HAL_OK)
  {
    Error_Handler();
  }
  /** Activate the Over-Drive mode
  */
  if (HAL_PWREx_EnableOverDrive() != HAL_OK)
  {
    Error_Handler();
  }
  /** Initializes the CPU, AHB and APB buses clocks
  */
  RCC_ClkInitStruct.ClockType = RCC_CLOCKTYPE_HCLK|RCC_CLOCKTYPE_SYSCLK
                              |RCC_CLOCKTYPE_PCLK1|RCC_CLOCKTYPE_PCLK2;
  RCC_ClkInitStruct.SYSCLKSource = RCC_SYSCLKSOURCE_PLLCLK;
  RCC_ClkInitStruct.AHBCLKDivider = RCC_SYSCLK_DIV1;
  RCC_ClkInitStruct.APB1CLKDivider = RCC_HCLK_DIV4;
  RCC_ClkInitStruct.APB2CLKDivider = RCC_HCLK_DIV2;

  if (HAL_RCC_ClockConfig(&RCC_ClkInitStruct, FLASH_LATENCY_5) != HAL_OK)
  {
    Error_Handler();
  }
  PeriphClkInitStruct.PeriphClockSelection = RCC_PERIPHCLK_CLK48;
  PeriphClkInitStruct.PLLSAI.PLLSAIM = 4;
  PeriphClkInitStruct.PLLSAI.PLLSAIN = 96;
  PeriphClkInitStruct.PLLSAI.PLLSAIQ = 2;
  PeriphClkInitStruct.PLLSAI.PLLSAIP = RCC_PLLSAIP_DIV4;
  PeriphClkInitStruct.PLLSAIDivQ = 1;
  PeriphClkInitStruct.Clk48ClockSelection = RCC_CLK48CLKSOURCE_PLLSAIP;
  if (HAL_RCCEx_PeriphCLKConfig(&PeriphClkInitStruct) != HAL_OK)
  {
    Error_Handler();
  }
}

static void MX_ADC1_Init(void)
{

  ADC_ChannelConfTypeDef sConfig = {0};

  /** Configure the global features of the ADC (Clock, Resolution, Data Alignment and number of conversion)
  */
  hadc1.Instance = ADC1;
  hadc1.Init.ClockPrescaler = ADC_CLOCK_SYNC_PCLK_DIV4;
  hadc1.Init.Resolution = ADC_RESOLUTION_12B;
  hadc1.Init.ScanConvMode = DISABLE;
  hadc1.Init.ContinuousConvMode = DISABLE;
  hadc1.Init.DiscontinuousConvMode = DISABLE;
  hadc1.Init.ExternalTrigConvEdge = ADC_EXTERNALTRIGCONVEDGE_NONE;
  hadc1.Init.ExternalTrigConv = ADC_SOFTWARE_START;
  hadc1.Init.DataAlign = ADC_DATAALIGN_RIGHT;
  hadc1.Init.NbrOfConversion = 1;
  hadc1.Init.DMAContinuousRequests = DISABLE;
  hadc1.Init.EOCSelection = ADC_EOC_SINGLE_CONV;
  if (HAL_ADC_Init(&hadc1) != HAL_OK)
  {
    Error_Handler();
  }
  /** Configure for the selected ADC regular channel its corresponding rank in the sequencer and its sample time.
  */
  sConfig.Channel = ADC_CHANNEL_12;
  sConfig.Rank = 1;
  sConfig.SamplingTime = ADC_SAMPLETIME_3CYCLES;
  if (HAL_ADC_ConfigChannel(&hadc1, &sConfig) != HAL_OK)
  {
    Error_Handler();
  }

}

static void MX_I2C3_Init(void)
{

  hi2c3.Instance = I2C3;
  hi2c3.Init.ClockSpeed = 400000;
  hi2c3.Init.DutyCycle = I2C_DUTYCYCLE_2;
  hi2c3.Init.OwnAddress1 = 0;
  hi2c3.Init.AddressingMode = I2C_ADDRESSINGMODE_7BIT;
  hi2c3.Init.DualAddressMode = I2C_DUALADDRESS_DISABLE;
  hi2c3.Init.OwnAddress2 = 0;
  hi2c3.Init.GeneralCallMode = I2C_GENERALCALL_DISABLE;
  hi2c3.Init.NoStretchMode = I2C_NOSTRETCH_DISABLE;
  if (HAL_I2C_Init(&hi2c3) != HAL_OK)
  {
    Error_Handler();
  }

}

static void MX_SPI1_Init(void)
{

  /* SPI1 parameter configuration*/
  hspi1.Instance = SPI1;
  hspi1.Init.Mode = SPI_MODE_MASTER;
  hspi1.Init.Direction = SPI_DIRECTION_2LINES;
  hspi1.Init.DataSize = SPI_DATASIZE_8BIT;
  hspi1.Init.CLKPolarity = SPI_POLARITY_LOW;
  hspi1.Init.CLKPhase = SPI_PHASE_1EDGE;
  hspi1.Init.NSS = SPI_NSS_SOFT;
  hspi1.Init.BaudRatePrescaler = SPI_BAUDRATEPRESCALER_16;
  hspi1.Init.FirstBit = SPI_FIRSTBIT_MSB;
  hspi1.Init.TIMode = SPI_TIMODE_DISABLE;
  hspi1.Init.CRCCalculation = SPI_CRCCALCULATION_DISABLE;
  hspi1.Init.CRCPolynomial = 10;
  if (HAL_SPI_Init(&hspi1) != HAL_OK)
  {
    Error_Handler();
  }

}

static void MX_SPI2_Init(void)
{

  /* SPI2 parameter configuration*/
  hspi2.Instance = SPI2;
  hspi2.Init.Mode = SPI_MODE_MASTER;
  hspi2.Init.Direction = SPI_DIRECTION_2LINES;
  hspi2.Init.DataSize = SPI_DATASIZE_8BIT;
  hspi2.Init.CLKPolarity = SPI_POLARITY_LOW;
  hspi2.Init.CLKPhase = SPI_PHASE_1EDGE;
  hspi2.Init.NSS = SPI_NSS_SOFT;
  hspi2.Init.BaudRatePrescaler = SPI_BAUDRATEPRESCALER_8;
  hspi2.Init.FirstBit = SPI_FIRSTBIT_MSB;
  hspi2.Init.TIMode = SPI_TIMODE_DISABLE;
  hspi2.Init.CRCCalculation = SPI_CRCCALCULATION_DISABLE;
  hspi2.Init.CRCPolynomial = 10;
  if (HAL_SPI_Init(&hspi2) != HAL_OK)
  {
    Error_Handler();
  }

}

static void MX_SPI3_Init(void)
{

  /* SPI3 parameter configuration*/
  hspi3.Instance = SPI3;
  hspi3.Init.Mode = SPI_MODE_MASTER;
  hspi3.Init.Direction = SPI_DIRECTION_2LINES;
  hspi3.Init.DataSize = SPI_DATASIZE_8BIT;
  hspi3.Init.CLKPolarity = SPI_POLARITY_LOW;
  hspi3.Init.CLKPhase = SPI_PHASE_1EDGE;
  hspi3.Init.NSS = SPI_NSS_SOFT;
  hspi3.Init.BaudRatePrescaler = SPI_BAUDRATEPRESCALER_8;
  hspi3.Init.FirstBit = SPI_FIRSTBIT_MSB;
  hspi3.Init.TIMode = SPI_TIMODE_DISABLE;
  hspi3.Init.CRCCalculation = SPI_CRCCALCULATION_DISABLE;
  hspi3.Init.CRCPolynomial = 10;
  if (HAL_SPI_Init(&hspi3) != HAL_OK)
  {
    Error_Handler();
  }

}

static void MX_TIM2_Init(void)
{

  TIM_MasterConfigTypeDef sMasterConfig = {0};
  TIM_OC_InitTypeDef sConfigOC = {0};

  htim2.Instance = TIM2;
  htim2.Init.Prescaler = 90-1;
  htim2.Init.CounterMode = TIM_COUNTERMODE_UP;
  htim2.Init.Period = 20000-1;
  htim2.Init.ClockDivision = TIM_CLOCKDIVISION_DIV1;
  htim2.Init.AutoReloadPreload = TIM_AUTORELOAD_PRELOAD_DISABLE;
  if (HAL_TIM_PWM_Init(&htim2) != HAL_OK)
  {
    Error_Handler();
  }
  sMasterConfig.MasterOutputTrigger = TIM_TRGO_RESET;
  sMasterConfig.MasterSlaveMode = TIM_MASTERSLAVEMODE_DISABLE;
  if (HAL_TIMEx_MasterConfigSynchronization(&htim2, &sMasterConfig) != HAL_OK)
  {
    Error_Handler();
  }
  sConfigOC.OCMode = TIM_OCMODE_PWM1;
  sConfigOC.Pulse = 0;
  sConfigOC.OCPolarity = TIM_OCPOLARITY_HIGH;
  sConfigOC.OCFastMode = TIM_OCFAST_DISABLE;
  if (HAL_TIM_PWM_ConfigChannel(&htim2, &sConfigOC, TIM_CHANNEL_2) != HAL_OK)
  {
    Error_Handler();
  }
  if (HAL_TIM_PWM_ConfigChannel(&htim2, &sConfigOC, TIM_CHANNEL_4) != HAL_OK)
  {
    Error_Handler();
  }
  HAL_TIM_MspPostInit(&htim2);

}

static void MX_TIM3_Init(void)
{

  TIM_ClockConfigTypeDef sClockSourceConfig = {0};
  TIM_MasterConfigTypeDef sMasterConfig = {0};
  TIM_OC_InitTypeDef sConfigOC = {0};

  htim3.Instance = TIM3;
  htim3.Init.Prescaler = 90-1;
  htim3.Init.CounterMode = TIM_COUNTERMODE_UP;
  htim3.Init.Period = 256-1;
  htim3.Init.ClockDivision = TIM_CLOCKDIVISION_DIV1;
  htim3.Init.AutoReloadPreload = TIM_AUTORELOAD_PRELOAD_DISABLE;
  if (HAL_TIM_Base_Init(&htim3) != HAL_OK)
  {
    Error_Handler();
  }
  sClockSourceConfig.ClockSource = TIM_CLOCKSOURCE_INTERNAL;
  if (HAL_TIM_ConfigClockSource(&htim3, &sClockSourceConfig) != HAL_OK)
  {
    Error_Handler();
  }
  if (HAL_TIM_PWM_Init(&htim3) != HAL_OK)
  {
    Error_Handler();
  }
  sMasterConfig.MasterOutputTrigger = TIM_TRGO_RESET;
  sMasterConfig.MasterSlaveMode = TIM_MASTERSLAVEMODE_DISABLE;
  if (HAL_TIMEx_MasterConfigSynchronization(&htim3, &sMasterConfig) != HAL_OK)
  {
    Error_Handler();
  }
  sConfigOC.OCMode = TIM_OCMODE_PWM1;
  sConfigOC.Pulse = 0;
  sConfigOC.OCPolarity = TIM_OCPOLARITY_LOW;
  sConfigOC.OCFastMode = TIM_OCFAST_DISABLE;
  if (HAL_TIM_PWM_ConfigChannel(&htim3, &sConfigOC, TIM_CHANNEL_1) != HAL_OK)
  {
    Error_Handler();
  }
  sConfigOC.OCPolarity = TIM_OCPOLARITY_HIGH;
  if (HAL_TIM_PWM_ConfigChannel(&htim3, &sConfigOC, TIM_CHANNEL_2) != HAL_OK)
  {
    Error_Handler();
  }
  sConfigOC.OCPolarity = TIM_OCPOLARITY_LOW;
  if (HAL_TIM_PWM_ConfigChannel(&htim3, &sConfigOC, TIM_CHANNEL_3) != HAL_OK)
  {
    Error_Handler();
  }
  if (HAL_TIM_PWM_ConfigChannel(&htim3, &sConfigOC, TIM_CHANNEL_4) != HAL_OK)
  {
    Error_Handler();
  }
  HAL_TIM_MspPostInit(&htim3);

}

static void MX_TIM6_Init(void)
{

  TIM_MasterConfigTypeDef sMasterConfig = {0};

  htim6.Instance = TIM6;
  htim6.Init.Prescaler = 90-1;
  htim6.Init.CounterMode = TIM_COUNTERMODE_UP;
  htim6.Init.Period = 65535;
  htim6.Init.AutoReloadPreload = TIM_AUTORELOAD_PRELOAD_DISABLE;
  if (HAL_TIM_Base_Init(&htim6) != HAL_OK)
  {
    Error_Handler();
  }
  sMasterConfig.MasterOutputTrigger = TIM_TRGO_RESET;
  sMasterConfig.MasterSlaveMode = TIM_MASTERSLAVEMODE_DISABLE;
  if (HAL_TIMEx_MasterConfigSynchronization(&htim6, &sMasterConfig) != HAL_OK)
  {
    Error_Handler();
  }

}

static void MX_DMA_Init(void)
{

  /* DMA controller clock enable */
  __HAL_RCC_DMA1_CLK_ENABLE();
  __HAL_RCC_DMA2_CLK_ENABLE();

  /* DMA interrupt init */
  /* DMA1_Stream3_IRQn interrupt configuration */
  HAL_NVIC_SetPriority(DMA1_Stream3_IRQn, 5, 0);
  HAL_NVIC_EnableIRQ(DMA1_Stream3_IRQn);
  /* DMA1_Stream4_IRQn interrupt configuration */
  HAL_NVIC_SetPriority(DMA1_Stream4_IRQn, 5, 0);
  HAL_NVIC_EnableIRQ(DMA1_Stream4_IRQn);
  /* DMA2_Stream3_IRQn interrupt configuration */
  HAL_NVIC_SetPriority(DMA2_Stream3_IRQn, 5, 0);
  HAL_NVIC_EnableIRQ(DMA2_Stream3_IRQn);

}

static void MX_GPIO_Init(void)
{
  GPIO_InitTypeDef GPIO_InitStruct = {0};

  /* GPIO Ports Clock Enable */
  __HAL_RCC_GPIOC_CLK_ENABLE();
  __HAL_RCC_GPIOH_CLK_ENABLE();
  __HAL_RCC_GPIOA_CLK_ENABLE();
  __HAL_RCC_GPIOB_CLK_ENABLE();
  __HAL_RCC_GPIOD_CLK_ENABLE();

  /*Configure GPIO pin Output Level */
  HAL_GPIO_WritePin(GPIOA, CAM_POWER_Pin|FLASH_NSS_Pin|LORA_NSS_Pin, GPIO_PIN_RESET);

  /*Configure GPIO pin Output Level */
  HAL_GPIO_WritePin(GPIOC, SD_NSS_Pin|VTX_BTN1_Pin, GPIO_PIN_RESET);

  /*Configure GPIO pin Output Level */
  HAL_GPIO_WritePin(SPI2_NSS_GPIO_Port, SPI2_NSS_Pin, GPIO_PIN_RESET);

  /*Configure GPIO pin Output Level */
  HAL_GPIO_WritePin(LORA_RESET_GPIO_Port, LORA_RESET_Pin, GPIO_PIN_SET);

  /*Configure GPIO pin : IMU_INT_Pin */
  GPIO_InitStruct.Pin = IMU_INT_Pin;
  GPIO_InitStruct.Mode = GPIO_MODE_IT_RISING;
  GPIO_InitStruct.Pull = GPIO_NOPULL;
  HAL_GPIO_Init(IMU_INT_GPIO_Port, &GPIO_InitStruct);

  /*Configure GPIO pins : RBF_Pin EXPORT_BLACKBOX_Pin */
  GPIO_InitStruct.Pin = RBF_Pin|EXPORT_BLACKBOX_Pin;
  GPIO_InitStruct.Mode = GPIO_MODE_INPUT;
  GPIO_InitStruct.Pull = GPIO_PULLUP;
  HAL_GPIO_Init(GPIOA, &GPIO_InitStruct);

  /*Configure GPIO pins : CAM_POWER_Pin FLASH_NSS_Pin LORA_NSS_Pin */
  GPIO_InitStruct.Pin = CAM_POWER_Pin|FLASH_NSS_Pin|LORA_NSS_Pin;
  GPIO_InitStruct.Mode = GPIO_MODE_OUTPUT_PP;
  GPIO_InitStruct.Pull = GPIO_NOPULL;
  GPIO_InitStruct.Speed = GPIO_SPEED_FREQ_LOW;
  HAL_GPIO_Init(GPIOA, &GPIO_InitStruct);

  /*Configure GPIO pin : SD_NSS_Pin */
  GPIO_InitStruct.Pin = SD_NSS_Pin;
  GPIO_InitStruct.Mode = GPIO_MODE_OUTPUT_PP;
  GPIO_InitStruct.Pull = GPIO_NOPULL;
  GPIO_InitStruct.Speed = GPIO_SPEED_FREQ_LOW;
  HAL_GPIO_Init(SD_NSS_GPIO_Port, &GPIO_InitStruct);

  /*Configure GPIO pin : VTX_BTN1_Pin */
  GPIO_InitStruct.Pin = VTX_BTN1_Pin;
  GPIO_InitStruct.Mode = GPIO_MODE_OUTPUT_PP;
  GPIO_InitStruct.Pull = GPIO_PULLDOWN;
  GPIO_InitStruct.Speed = GPIO_SPEED_FREQ_LOW;
  HAL_GPIO_Init(VTX_BTN1_GPIO_Port, &GPIO_InitStruct);

  /*Configure GPIO pins : SPI2_NSS_Pin LORA_RESET_Pin */
  GPIO_InitStruct.Pin = SPI2_NSS_Pin|LORA_RESET_Pin;
  GPIO_InitStruct.Mode = GPIO_MODE_OUTPUT_PP;
  GPIO_InitStruct.Pull = GPIO_NOPULL;
  GPIO_InitStruct.Speed = GPIO_SPEED_FREQ_LOW;
  HAL_GPIO_Init(GPIOB, &GPIO_InitStruct);

  /*Configure GPIO pin : LORA_DIO1_Pin */
  GPIO_InitStruct.Pin = LORA_DIO1_Pin;
  GPIO_InitStruct.Mode = GPIO_MODE_INPUT;
  GPIO_InitStruct.Pull = GPIO_NOPULL;
  HAL_GPIO_Init(LORA_DIO1_GPIO_Port, &GPIO_InitStruct);

  /*Configure GPIO pin : LORA_BUSY_Pin */
  GPIO_InitStruct.Pin = LORA_BUSY_Pin;
  GPIO_InitStruct.Mode = GPIO_MODE_INPUT;
  GPIO_InitStruct.Pull = GPIO_NOPULL;
  HAL_GPIO_Init(LORA_BUSY_GPIO_Port, &GPIO_InitStruct);

  /*Configure GPIO pin : SD_DETECT_Pin */
  GPIO_InitStruct.Pin = SD_DETECT_Pin;
  GPIO_InitStruct.Mode = GPIO_MODE_INPUT;
  GPIO_InitStruct.Pull = GPIO_NOPULL;
  HAL_GPIO_Init(SD_DETECT_GPIO_Port, &GPIO_InitStruct);

  /*Configure GPIO pins : BREAKWIRE_Pin ARM_Pin */
  GPIO_InitStruct.Pin = BREAKWIRE_Pin|ARM_Pin;
  GPIO_InitStruct.Mode = GPIO_MODE_INPUT;
  GPIO_InitStruct.Pull = GPIO_PULLUP;
  HAL_GPIO_Init(GPIOB, &GPIO_InitStruct);

  /* EXTI interrupt init*/
  HAL_NVIC_SetPriority(EXTI15_10_IRQn, 5, 0);
  HAL_NVIC_EnableIRQ(EXTI15_10_IRQn);

}

/* USER CODE BEGIN 4 */

void playtone(uint16_t freq, uint16_t ms, uint8_t vol) {

    // 90MHz / (90 * ARR) = freq
    // 90MHz / (90 * freq) = ARR
    // 1MHz/(freq) = AAR

    // save LED's
    uint16_t ledR = htim3.Instance->CCR3;
    uint16_t ledG = htim3.Instance->CCR1;
    uint16_t ledB = htim3.Instance->CCR4;

    uint32_t aar_val = 1e6 / (freq);
    htim3.Instance->CNT = 0;
    htim3.Instance->ARR = aar_val;
    htim3.Instance->CCR2 = aar_val * vol / (2 * 100);
    // same LED brightness
    htim3.Instance->CCR3 = (aar_val * ledR) / 256;
    htim3.Instance->CCR1 = (aar_val * ledG) / 256;
    htim3.Instance->CCR4 = (aar_val * ledB) / 256;

    HAL_Delay(ms);

    // reset to defaults
    htim3.Instance->CCR2 = 0;
    htim3.Instance->ARR = 256 - 1;

    // back to normal LED
    htim3.Instance->CCR3 = ledR;
    htim3.Instance->CCR1 = ledG;
    htim3.Instance->CCR4 = ledB;
}

void playtoneRTOS(uint16_t freq, uint16_t ms, uint8_t vol) {

    // 90MHz / (90 * ARR) = freq
    // 90MHz / (90 * freq) = ARR
    // 1MHz/(freq) = AAR

    // save LED's
    uint16_t ledR = htim3.Instance->CCR3;
    uint16_t ledG = htim3.Instance->CCR1;
    uint16_t ledB = htim3.Instance->CCR4;

    uint32_t aar_val = 1e6 / (freq);
    htim3.Instance->CNT = 0;
    htim3.Instance->ARR = aar_val;
    htim3.Instance->CCR2 = aar_val * vol / (2 * 100);
    // same LED brightness
    htim3.Instance->CCR3 = (aar_val * ledR) / 256;
    htim3.Instance->CCR1 = (aar_val * ledG) / 256;
    htim3.Instance->CCR4 = (aar_val * ledB) / 256;

    osDelay(ms);

    // reset to defaults
    htim3.Instance->CCR2 = 0;
    htim3.Instance->ARR = 256 - 1;

    // back to normal LED
    htim3.Instance->CCR3 = ledR;
    htim3.Instance->CCR1 = ledG;
    htim3.Instance->CCR4 = ledB;
}

void changeLed(uint8_t ledR, uint8_t ledG, uint8_t ledB) {
    htim3.Instance->CCR3 = ledR;
    htim3.Instance->CCR1 = ledG;
    htim3.Instance->CCR4 = ledB;

}

#define G0 784
#define A0 880
#define B0 988
#define C1 1047
#define D1 1175
#define E1 1319
#define F1 1397
#define G1 1568
#define A1 1760

void jingleBell() {
    uint16_t vol = 10;
    uint16_t wait1 = 125;
    uint16_t wait2 = 255;

    uint16_t tones[] = { E1, E1, E1, E1, E1, E1,
    E1, G1, C1, D1, E1,
    F1, F1, F1, F1, F1, E1, E1,
    E1, E1, D1, D1, E1, D1, G1,

    E1, E1, E1, E1, E1, E1,
    E1, G1, C1, D1, E1,
    F1, F1, F1, F1, F1, E1, E1,
    E1, G1, G1, F1, D1, C1 };

    uint16_t tonelength[] = { wait1, wait1, wait2, wait1, wait1, wait2, wait1,
            wait1, wait1, wait1, wait2, wait1, wait1, wait1, wait1, wait1,
            wait1, wait1, wait1, wait1, wait1, wait1, wait1, wait2, wait2,

            wait1, wait1, wait2, wait1, wait1, wait2, wait1, wait1, wait1,
            wait1, wait2, wait1, wait1, wait1, wait1, wait1, wait1, wait1,
            wait1, wait1, wait1, wait1, wait1, wait2 };

    uint16_t delays[] = { wait1, wait1, wait2, wait1, wait1, wait2, wait1,
            wait1, wait1, wait1, wait1 * 3, wait1, wait1, wait1, wait1, wait1,
            wait1, wait1, wait1, wait1, wait1, wait1, wait1, wait2, wait2,

            wait1, wait1, wait2, wait1, wait1, wait2, wait1, wait1, wait1,
            wait1, wait1 * 3, wait1, wait1, wait1, wait1, wait1, wait1, wait1,
            wait1, wait1, wait1, wait1, wait1, wait2 };

    uint8_t num_notes = sizeof(tonelength) / sizeof(uint16_t);

    for (uint8_t i = 0; i < num_notes; i++) {
        playtone(tones[i], tonelength[i], vol);
        HAL_Delay(delays[i]);
    }

}

void rick() {
    uint16_t vol = 10;
    uint16_t beatlength = 50; // determines tempo
    float beatseparationconstant = 0.3;

    uint16_t song1_intro_melody[] = { c5s, e5f, e5f, f5, a5f, f5s, f5, e5f, c5s,
    e5f, rest, a4f, a4f };

    uint16_t song1_intro_rhythmn[] =
            { 6, 10, 6, 6, 1, 1, 1, 1, 6, 10, 4, 2, 10 };

    uint16_t song1_verse1_melody[] = { rest, c4s, c4s, c4s, c4s, e4f, rest, c4,
    b3f, a3f,
    rest, b3f, b3f, c4, c4s, a3f, a4f, a4f, e4f,
    rest, b3f, b3f, c4, c4s, b3f, c4s, e4f, rest, c4, b3f, b3f, a3f,
    rest, b3f, b3f, c4, c4s, a3f, a3f, e4f, e4f, e4f, f4, e4f,
    c4s, e4f, f4, c4s, e4f, e4f, e4f, f4, e4f, a3f,
    rest, b3f, c4, c4s, a3f, rest, e4f, f4, e4f };

    uint16_t song1_verse1_rhythmn[] = { 2, 1, 1, 1, 1, 2, 1, 1, 1, 5, 1, 1, 1,
            1, 3, 1, 2, 1, 5, 1, 1, 1, 1, 1, 1, 1, 2, 1, 1, 1, 1, 3, 1, 1, 1, 1,
            2, 1, 1, 1, 1, 1, 1, 4, 5, 1, 1, 1, 1, 1, 1, 1, 2, 2, 2, 1, 1, 1, 3,
            1, 1, 1, 3 };

    uint16_t song1_chorus_melody[] = { b4f, b4f, a4f, a4f,
    f5, f5, e5f, b4f, b4f, a4f, a4f, e5f, e5f, c5s, c5, b4f,
    c5s, c5s, c5s, c5s,
    c5s, e5f, c5, b4f, a4f, a4f, a4f, e5f, c5s,
    b4f, b4f, a4f, a4f,
    f5, f5, e5f, b4f, b4f, a4f, a4f, a5f, c5, c5s, c5, b4f,
    c5s, c5s, c5s, c5s,
    c5s, e5f, c5, b4f, a4f, rest, a4f, e5f, c5s, rest };

    uint16_t song1_chorus_rhythmn[] =
            { 1, 1, 1, 1, 3, 3, 6, 1, 1, 1, 1, 3, 3, 3, 1, 2, 1, 1, 1, 1, 3, 3,
                    3, 1, 2, 2, 2, 4, 8, 1, 1, 1, 1, 3, 3, 6, 1, 1, 1, 1, 3, 3,
                    3, 1, 2, 1, 1, 1, 1, 3, 3, 3, 1, 2, 2, 2, 4, 8, 4 };

    int a = 4; // part index
    int b = 0; // song index
    int c; // lyric index

    while (1) {

        uint16_t notelength;
        if (a == 1 || a == 2) {
            // intro
            notelength = beatlength * song1_intro_rhythmn[b];
            if (song1_intro_melody[b] > 0) {
                playtone(song1_intro_melody[b], notelength, vol);
            }
            b++;
            if (b >= sizeof(song1_intro_melody) / sizeof(uint16_t)) {
                a++;
                b = 0;
                c = 0;
            }
        } else if (a == 3 || a == 5) {
            // verse
            notelength = beatlength * 2 * song1_verse1_rhythmn[b];
            if (song1_verse1_melody[b] > 0) {
                playtone(song1_verse1_melody[b], notelength, vol);
                c++;
            }
            b++;
            if (b >= sizeof(song1_verse1_melody) / sizeof(uint16_t)) {
                a++;
                b = 0;
                c = 0;
            }
        } else if (a == 4 || a == 6) {
            // chorus
            notelength = beatlength * song1_chorus_rhythmn[b];
            if (song1_chorus_melody[b] > 0) {
                playtone(song1_chorus_melody[b], notelength, vol);
                c++;
            }
            b++;
            if (b >= sizeof(song1_chorus_melody) / sizeof(uint16_t)) {
                a++;
                b = 0;
                c = 0;
            }
        }

        HAL_Delay(notelength);
        //noTone(piezo);

        HAL_Delay(notelength * beatseparationconstant);
        if (a == 7) { // loop back around to beginning of song
            a = 1;
        }
    }

}

void ksp() {
    int vol = 20;
    playtone(659, 1000, vol); // EHigh
    playtone(523, 1000, vol); //
    playtone(783, 1000, vol);
    playtone(523, 333, vol);
    playtone(659, 333, vol);
    playtone(784, 333, vol);
    playtone(932, 1000, vol);
    playtone(880, 1000, vol);
    playtone(784, 1000, vol);
    playtone(523, 333, vol);
    playtone(659, 333, vol);
    playtone(784, 333, vol);
    playtone(932, 1000, vol);
    playtone(880, 1000, vol);
    playtone(784, 1000, vol);
    playtone(523, 1000, vol);
    playtone(587, 1000, vol);
    playtone(698, 2000, vol);
    playtone(587, 500, vol);
    playtone(523, 500, vol);
}

/* USER CODE END 4 */

void StartLedTask(void const * argument)
{
  /* init code for USB_DEVICE */
  MX_USB_DEVICE_Init();
  /* USER CODE BEGIN 5 */
    /* Infinite loop */
    for (;;) {
        //changeLed(0, 100, 0);
        osDelay(1000);
        //changeLed(0, 0, 100);
        osDelay(1000);
    }
  /* USER CODE END 5 */
}

void StartMusicTask(void const * argument)
{
  /* USER CODE BEGIN StartMusicTask */
    /* Infinite loop */

    uint16_t vol = 13; // 13
    uint16_t beatlength = 50; // determines tempo
    float beatseparationconstant = 0.3;

    int a = 4; // part index
    int b = 0; // song index
    int c; // lyric index

    osEvent messagebox;
    uint16_t sounddelay;

    int ksp_playhead = 0;
    int ksp_total = 20;

    for (;;) {
        if (is_soft_enabled()) {
            messagebox = osMessageGet(BuzzerQueueHandle, 1000);
            if (messagebox.status && messagebox.value.v) {
                sounddelay = messagebox.value.v;
                playtoneRTOS(OPTIMAL_BUZZER_FREQ, sounddelay,
                        OPTIMAL_BUZZER_DUTY);
                osDelay(sounddelay);
            }

        }
        else if (buzzer_setting == RICK){
            uint16_t notelength;
            if (a == 1 || a == 2) {
                // intro
                notelength = beatlength * song1_intro_rhythmn[b];
                if (song1_intro_melody[b] > 0) {
                    playtoneRTOS(song1_intro_melody[b], notelength, vol);
                }
                b++;
                if (b >= sizeof(song1_intro_melody) / sizeof(uint16_t)) {
                    a++;
                    b = 0;
                    c = 0;
                }
            } else if (a == 3 || a == 5) {
                // verse
                notelength = beatlength * 2 * song1_verse1_rhythmn[b];
                if (song1_verse1_melody[b] > 0) {
                    playtoneRTOS(song1_verse1_melody[b], notelength, vol);
                    c++;
                }
                b++;
                if (b >= sizeof(song1_verse1_melody) / sizeof(uint16_t)) {
                    a++;
                    b = 0;
                    c = 0;
                }
            } else if (a == 4 || a == 6) {
                // chorus
                notelength = beatlength * song1_chorus_rhythmn[b];
                if (song1_chorus_melody[b] > 0) {
                    playtoneRTOS(song1_chorus_melody[b], notelength, vol);
                    c++;
                }
                b++;
                if (b >= sizeof(song1_chorus_melody) / sizeof(uint16_t)) {
                    a++;
                    b = 0;
                    c = 0;
                }
            }

            osDelay(notelength);
            //noTone(piezo);

            osDelay(notelength * beatseparationconstant);
            if (a == 7) { // loop back around to beginning of song
                a = 1;
            }
        }
        else if (buzzer_setting == KSP_MAIN) {
            playtoneRTOS(ksp_tunes[ksp_playhead], ksp_delays[ksp_playhead], vol);
            ksp_playhead = (ksp_playhead + 1) % ksp_total;
        }
    }
  /* USER CODE END StartMusicTask */
}

void startStateMachine(void const * argument)
{
  /* USER CODE BEGIN startStateMachine */

    uint32_t launchTime = osKernelSysTick();
    uint32_t currentTime = osKernelSysTick();
    uint32_t timeSinceLaunch = 0;
    Servo deployServo;
    servo_init(&deployServo, &htim2, &htim2.Instance->CCR4);
    servo_disable(&deployServo);
    servo_setting = 0;
    uint8_t cam_has_toggled = 0;

    /* Infinite loop */
    for (;;) {

        currentTime = osKernelSysTick();
        timeSinceLaunch = currentTime - launchTime;

        if (is_soft_enabled()) {

            float vbat = get_battery_voltage();

            if (vbat < 7.2) {
                disable_camera();
            }

            switch (flight_state) {
            case FLIGHT_ERROR:
                // be annoying TODO
                buzzer_beep(BEEP_LONG);
                is_data_logging = 0;

                // exit the state once we're no longer armed,
                // if battery voltage is in good state
                // and if there's a squib connected if one is necessary
                changeLed(0, 0, 0);
                if (!is_armed() && get_battery_voltage() > BATTERY_EMPTY_LIMIT) {
                    buzzer_clear_queue();

                    buzzer_beep(BEEP_SHORT);
                    buzzer_beep(BEEP_SHORT);
                    //set_status_led(ON);
                    flight_state = IDLE;
                }
                break;

            case SYSTEMS_CHECK:
                // this state is the entry state, it performs startup checking of some peripherals
                changeLed(100, 0, 0);
                apply_complementary = 1;
                is_data_logging = 0;
                // close the servo if necessary
                servo_writeangle(&deployServo, SERVO_CLOSED_POSITION);
                servo_setting = 1;

                // enable power to camera/video transmitter
                if (vbat > 7.4) {
                    restart_camera_with_recording();
                } else {
                    disable_camera();
                }

                // check if the battery is empty
                if (vbat <= BATTERY_EMPTY_LIMIT) {
                    flight_state = FLIGHT_ERROR;
                    break;
                }

                // if everything's okay, go into idle
                buzzer_beep(BEEP_SHORT);
                buzzer_beep(BEEP_SHORT);
                set_status_led(1);
                flight_state = IDLE;
                break;

            case IDLE:
                changeLed(0, 100, 0);
                is_data_logging = 0;
                apply_complementary = 1;
                if (is_armed()) {
                    flight_state = FLIGHT_ERROR;
                    break;
                }

                if (is_breakwire_connected()) {
                    buzzer_beep(BEEP_SHORT);
                    buzzer_beep(BEEP_SHORT);
                    set_status_led(0);
                    flight_state = PREPARATION;
                    break;
                }
                break;

            case PREPARATION:
                changeLed(0, 0, 100);
                apply_complementary = 1;
                is_data_logging = 0;
                if (is_breakwire_broken_debounce()) {
                    buzzer_beep(BEEP_LONG);
                    set_status_led(1);
                    flight_state = IDLE;
                    break;
                }

                // check arming switch with debouncing
                if (is_armed_debounce()) {
                    buzzer_beep(BEEP_SHORT);
                    buzzer_beep(BEEP_SHORT);
                    set_status_led(1);
                    flight_state = ARMED;
                }
                break;

            case ARMED:
                is_data_logging = 1;
                changeLed(100, 100, 0);
                apply_complementary = 1;
                if (!is_armed()) {
                    buzzer_beep(BEEP_LONG);
                    set_status_led(0);
                    flight_state = PREPARATION;
                    break;
                }

                if (is_breakwire_broken_debounce()) {
                    //reset_timer();

                    launchTime = currentTime;

                    //set_launch_asserted(ON);
                    flight_state = LAUNCHED;
                    cam_has_toggled = 0;
                    break;
                }
                break;

            case LAUNCHED:
                is_data_logging = 1;
                changeLed(100, 100, 100);
                apply_complementary = 0;
                buzzer_beep(BEEP_SHORT);
                buzzer_beep(BEEP_SHORT);

                if (timeSinceLaunch >= MAX_DEPLOY_TIME
                        || (timeSinceLaunch >= MIN_DEPLOY_TIME
                                && is_vote_asserted())) {

                    if (is_armed()) {
                        servo_writeangle(&deployServo, SERVO_DEPLOY_POSITION);
                        servo_setting = 2;

                        last_logged_deploy_time = timeSinceLaunch;
                        buzzer_clear_queue();
                        flight_state = DEPLOYED;
                        break;
                    } else { // go back to systems check if rearmed
                        flight_state = SYSTEMS_CHECK;
                        break;
                    }
                }
                break;

            case DEPLOYED:
                is_data_logging = 1;
                changeLed(100, 0, 100);
                buzzer_beep(BEEP_LONG);

                if (!cam_has_toggled && baro.altitude < 100) {
                    pulse_recording_button();
                    osDelay(400);
                    pulse_recording_button();
                    cam_has_toggled = 1;
                }

                if (timeSinceLaunch > 240000) { // 4 min after launch
                    flight_state = LANDED;
                }

                break;

            case LANDED:
                is_data_logging = 0;
                buzzer_beep(BEEP_LONG);
                disable_camera();
                break;
            }
        } else {
            // when "soft on/off switch" is off. Play some music and disable everything
            apply_complementary = 1;
            is_data_logging = 0;
            changeLed(100, 0, 0);
            buzzer_setting = KSP_MAIN;
            flight_state = SYSTEMS_CHECK;
            servo_disable(&deployServo);
            servo_setting = 0;
            baro.basepressure = baro.pressure_Pa; // Continously "zero out" altitude when soft off
            disable_camera();
        }
        osDelay(1);
    }
  /* USER CODE END startStateMachine */
}

void StartTelemTask(void const * argument)
{
  /* USER CODE BEGIN StartTelemTask */
    sx1280_custom radio;

    sxInit(&radio, &hspi3, LORA_NSS_GPIO_Port, LORA_NSS_Pin);
    sxSetDio1Pin(&radio, LORA_DIO1_GPIO_Port, LORA_DIO1_Pin);

    SetTxParams(&radio, 0x1F, 0xE0); // Power = 13 dBm (0x1F), Pout = -18 + power (dBm) ramptime = 20 us.
    //SetTxParams(&radio, 0, 0xE0); // lowest power -18dBm
    osDelay(3);

    //lsm6dso imu;
    //uint8_t lsm_init_status = LSM_init(&imu, &hspi2, SPI2_NSS_GPIO_Port,SPI2_NSS_Pin);

    uint32_t counter = 0;

    TLM_decoded TLM_dec;
    TLM_encoded TLM_enc;

    TLM_dec.packet_type = 1;
    TLM_dec.flight_state = 4;
    TLM_dec.is_playing_music = 0;
    TLM_dec.is_data_logging = 0;
    TLM_dec.pin_states = 0b00011011;
    TLM_dec.servo_state = 3;
    TLM_dec.vbat = 7.283;
    TLM_dec.systick = 1232432;
    TLM_dec.orientation_quat[0] = 0.143123;
    TLM_dec.acc[2] = 1337;
    TLM_dec.gyro[2] = -21;
    TLM_dec.baro = 90001.623;
    TLM_dec.temp = 63.4;
    TLM_dec.vertical_velocity = 180;
    TLM_dec.altitude = 1321;
    TLM_dec.debug = 1337;
    TLM_dec.ranging = 15212;

    encode_TLM(&TLM_dec, &TLM_enc);

    WriteBuffer(&radio, 0, (uint8_t*) &TLM_enc, sizeof(TLM_enc));
    osDelay(1);

    SetDioIrqParams(&radio, 1 | (1 << 1) | (1<<9), 1 | (1 << 1) | (1<<9), 0, 0); // txdone and rxdone and rangingresultvalid on gpio1
    osDelay(1);
    sxStandardRangingMaster(&radio);

    osDelay(3);

    uint8_t rxData[4];

    uint32_t lasttime = HAL_GetTick();
    uint32_t nowtime = HAL_GetTick();
    //changeLed(100, 100, 100);
    /* Infinite loop */
    for (;;) {

        //LSM_pollsensors(&imu);
        //changeLed(0, 0, 100);
        //nowtime = HAL_GetTick();
        //dt = (nowtime - lasttime) / 1000.0;
        //lasttime = nowtime;

        counter++;

        for (int i = 0; i < 10; i++) {
            if (HAL_GPIO_ReadPin(LORA_DIO1_GPIO_Port, LORA_DIO1_Pin)) {
                break;
            }
            osDelay(3);
        }

        if (counter % 30 == 0) {
            // change to receive mode every second for two way radio
            SetPacketParamsLora(&radio, 12, 0x80, 4, 0x20, 0x40); // 4 byte payload
            osDelay(1);
            ClrIrqStatus(&radio, 1 | (1 << 1) | (1<<9));
            osDelay(1);
            SetRx(&radio, 0x02, 25);

            for (int i = 0; i < 25; i++) { // 25 ms timeout
                if (HAL_GPIO_ReadPin(LORA_DIO1_GPIO_Port, LORA_DIO1_Pin)) {
                    break;
                }
                HAL_Delay(1);
            }

            if (HAL_GPIO_ReadPin(LORA_DIO1_GPIO_Port, LORA_DIO1_Pin)) {
                // rxdone
                ReadBuffer(&radio, 0, sizeof(rxData), rxData);

                if (rxData[0] == 123 && rxData[1] == 100 && rxData[2] == 123 && rxData[3] == 100) {
                    // enable camera
                    if (!is_camera_recording) {
                        restart_camera_with_recording();
                    }
                }
                else if (rxData[0] == 12 && rxData[1] == 34 && rxData[2] == 56 && rxData[3] == 78) {
                    // disable camera
                    disable_camera();

                }
            }
            osDelay(1);

            SetPacketParamsLora(&radio, 12, 0x80, 32, 0x20, 0x40);

        }
        else if ((counter % 60 == 12 || counter % 60 == 24) && ranging_enabled) {
            // twice per second, try ranging
            ClrIrqStatus(&radio, 1 | (1 << 1) | (1<<9));
            osDelay(1);
            SetStandbyRC(&radio);
            osDelay(1);
            setPacketRanging(&radio);
            osDelay(1);
            SetModulationParams(&radio, 0x80, 0x18, 0x01);
            osDelay(1);
            SetPacketParamsLora(&radio, 12, 0x80, 0, 0x20, 0x40);
            osDelay(1);
            sxStandardRangingMaster(&radio);
            osDelay(1);
            SetRfFrequency(&radio);
            osDelay(1);
            SetTx(&radio, 0x02, 25); // time-out of 1ms * 30 = 30ms
            osDelay(1);

            for (int i = 0; i < 30; i++) { // 30 ms timeout
                if (HAL_GPIO_ReadPin(LORA_DIO1_GPIO_Port, LORA_DIO1_Pin)) {
                    break;
                }
                HAL_Delay(1);
            }

            if (HAL_GPIO_ReadPin(LORA_DIO1_GPIO_Port, LORA_DIO1_Pin) && 0) {
                SetStandbyXOSC(&radio);
                osDelay(1);
                uint8_t temp = (ReadRegisterByte(&radio, 0x0924) & 0xCF)
                        | (0b00000001 << 4); // Average RSSI filtered result
                // TODO
                SetStandbyRC(&radio);
                osDelay(1);
            }

            osDelay(1);
            SetRfFrequency2(&radio);
            osDelay(1);
            setPacketLora(&radio);
            osDelay(1);
            SetPacketParamsLora(&radio, 12, 0x80, 32, 0x20, 0x40);
        } else {
            TLM_dec.vbat = get_battery_voltage();
            TLM_dec.systick = osKernelSysTick();
            TLM_dec.is_data_logging = is_data_logging;
            TLM_dec.acc[0] = imu.rawAcc[0];
            TLM_dec.acc[1] = imu.rawAcc[1];
            TLM_dec.acc[2] = imu.rawAcc[2];
            TLM_dec.gyro[0] = imu.rawGyro[0];
            TLM_dec.gyro[1] = imu.rawGyro[1];
            TLM_dec.gyro[2] = imu.rawGyro[2];
            TLM_dec.orientation_quat[0] = ori.orientationQuat.w;
            TLM_dec.orientation_quat[1] = ori.orientationQuat.v[0];
            TLM_dec.orientation_quat[2] = ori.orientationQuat.v[1];
            TLM_dec.orientation_quat[3] = ori.orientationQuat.v[2];
            // SPL06_Read(&baro);
            TLM_dec.baro = baro.pressure_Pa;
            TLM_dec.temp = baro.temperature_C;
            TLM_dec.altitude = baro.altitude;
            TLM_dec.vertical_velocity = baro.vertical_speed;
            TLM_dec.flight_state = flight_state;
            TLM_dec.pin_states = (is_soft_enabled()) | (is_armed() << 1)
                    | (is_breakwire_connected() << 2) | (is_camera_on << 3);
            TLM_dec.servo_state = servo_setting;

            //sprintf(printBuffer, "Quaternion: %f, %f, %f, %f\r\n", data[0],
            //        data[1], data[2], data[3]);
            //sprintf(printBuffer, "Quaternion: %f, %f, %f, %f\r\n",data[0],ori.orientationQuat.v[0],ori.orientationQuat.v[1],ori.orientationQuat.v[2]);
            //CDC_Transmit_FS((uint8_t*) printBuffer,
            //        MIN(strlen(printBuffer), 128));

            encode_TLM(&TLM_dec, &TLM_enc);
            WriteBuffer(&radio, 0, (uint8_t*) &TLM_enc, sizeof(TLM_enc));
            //WriteBuffer(&radio, 0, (uint8_t*) data, sizeof(data));
            osDelay(1);
            ClrIrqStatus(&radio, 1 | (1 << 1) | (1<<9)); // clear txdone/rxdone irq
            osDelay(1);
            SetRfFrequency2(&radio);
            osDelay(1);
            SetTx(&radio, 0x02, 50); // time-out of 1ms * 50 = 50ms
        }

        osDelay(10);

    }
  /* USER CODE END StartTelemTask */
}

void StartBaroTask(void const * argument)
{
  /* USER CODE BEGIN StartBaroTask */
  /* Infinite loop */
    uint32_t counter = 0;
    float prevh = 0;
    uint32_t last_baro_time = osKernelSysTick();
    uint32_t new_baro_time = osKernelSysTick();
    for (;;) {
        float dt = ((float) __HAL_TIM_GET_COUNTER(&htim6))/1000000;
        __HAL_TIM_SET_COUNTER(&htim6,0);
        orientation_setGyro(&ori, imu.gyroRPS);
        orientation_setAcc(&ori, imu.accMPS);
        orientation_update(&ori, dt, apply_complementary);
        if (counter % 50 == 0) { // 20 Hz
            prevh = baro.altitude;
            SPL06_Read(&baro);
            new_baro_time = osKernelSysTick();
            baro.vertical_speed = (baro.altitude - prevh) / (new_baro_time - last_baro_time);
            last_baro_time = new_baro_time;
        }
        osDelay(1);
    }
  /* USER CODE END StartBaroTask */
}

void StartBlackboxTask(void const * argument)
{
  /* USER CODE BEGIN StartBlackboxTask */
    osDelay(1);
    W25qxx_Init();

    osDelay(1); // wait 10 sec.
    TLM_decoded TLM_dec;

    uint16_t current_page = 0;

    while (1) {
        while (!is_data_logging) {
            osDelay(10);
        }
        osDelay(5000);
        if (is_data_logging) {
            break;
        }
    }
    playtoneRTOS(1000, 100, 20);
    W25qxx_EraseChip(); // takes some time
    playtoneRTOS(1500, 100, 20);

    chunk_of_flash.blockinfo[0] = 123;
    chunk_of_flash.blockinfo[1] = 123;
    /* Infinite loop */
    for (;;) {

        if (is_data_logging) {

            for (int i = 0; i < 7; i++) {
                TLM_dec.vbat = get_battery_voltage();
                TLM_dec.systick = osKernelSysTick();
                TLM_dec.is_data_logging = is_data_logging;
                TLM_dec.acc[0] = imu.rawAcc[0];
                TLM_dec.acc[1] = imu.rawAcc[1];
                TLM_dec.acc[2] = imu.rawAcc[2];
                TLM_dec.gyro[0] = imu.rawGyro[0];
                TLM_dec.gyro[1] = imu.rawGyro[1];
                TLM_dec.gyro[2] = imu.rawGyro[2];
                TLM_dec.orientation_quat[0] = ori.orientationQuat.w;
                TLM_dec.orientation_quat[1] = ori.orientationQuat.v[0];
                TLM_dec.orientation_quat[2] = ori.orientationQuat.v[1];
                TLM_dec.orientation_quat[3] = ori.orientationQuat.v[2];
                // SPL06_Read(&baro);
                TLM_dec.baro = baro.pressure_Pa;
                TLM_dec.temp = baro.temperature_C;
                TLM_dec.altitude = baro.altitude;
                TLM_dec.vertical_velocity = baro.vertical_speed;
                TLM_dec.flight_state = flight_state;
                TLM_dec.pin_states = (is_soft_enabled()) | (is_armed() << 1)
                        | (is_breakwire_connected() << 2) | (is_camera_on << 3);
                TLM_dec.servo_state = servo_setting;

                encode_Blackbox(&TLM_dec, &chunk_of_flash.packets[i]);
                osDelay(5); // approx 200 Hz logging rate.
            }

            W25qxx_WritePage((uint8_t*) &chunk_of_flash, current_page, 0, 255);
            current_page = (current_page + 1) % 65536;

        }
        else {
            osDelay(10);
        }
        osDelay(1);
    }
  /* USER CODE END StartBlackboxTask */
}

 /**
  * @brief  Period elapsed callback in non blocking mode
  * @note   This function is called  when TIM1 interrupt took place, inside
  * HAL_TIM_IRQHandler(). It makes a direct call to HAL_IncTick() to increment
  * a global variable "uwTick" used as application time base.
  * @param  htim : TIM handle
  * @retval None
  */
void HAL_TIM_PeriodElapsedCallback(TIM_HandleTypeDef *htim)
{
  if (htim->Instance == TIM1) {
    HAL_IncTick();
  }
}

void Error_Handler(void)
{
    __disable_irq();
    while (1) {
    }
}

/************************ (C) COPYRIGHT STMicroelectronics *****END OF FILE****/
